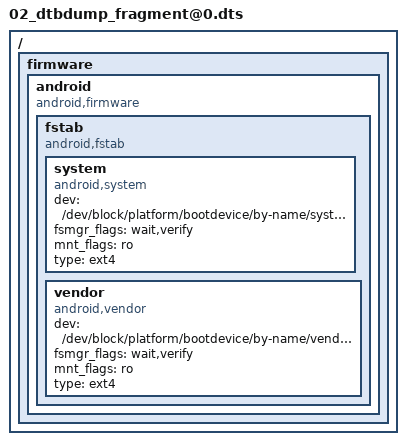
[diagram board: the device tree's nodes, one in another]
/dts-v1/;

/ {

	__fixups__ {
		accdet = "/fragment@15:target:0", "/fragment@66:target:0";
		apuart0 = "/fragment@20:target:0";
		audgpio = "/fragment@16:target:0";
		auxadc = "/fragment@45:target:0";
		charger = "/fragment@32:target:0";
		chosen = "/fragment@1:target:0";
		consys = "/fragment@19:target:0";
		dsi_te = "/fragment@70:target:0";
		fpc_interrupt = "/fragment@39:target:0";
		goodix_fp = "/fragment@68:target:0";
		goodix_optical_fp = "/fragment@42:target:0";
		gpio = "/fragment@60:target:0";
		gpio_usage_mapping = "/fragment@59:target:0";
		gyro = "/fragment@65:target:0";
		i2c0 = "/fragment@8:target:0", "/fragment@47:target:0";
		i2c1 = "/fragment@48:target:0";
		i2c10 = "/fragment@57:target:0";
		i2c11 = "/fragment@58:target:0";
		i2c2 = "/fragment@49:target:0";
		i2c3 = "/fragment@5:target:0", "/fragment@9:target:0", "/fragment@13:target:0", "/fragment@50:target:0";
		i2c4 = "/fragment@51:target:0";
		i2c5 = "/fragment@52:target:0";
		i2c6 = "/fragment@34:target:0", "/fragment@53:target:0", "/fragment@85:target:0";
		i2c7 = "/fragment@54:target:0";
		i2c8 = "/fragment@55:target:0";
		i2c9 = "/fragment@56:target:0";
		irq_nfc = "/fragment@63:target:0";
		irtx_pwm = "/fragment@22:target:0";
		kd_camera_hw1 = "/fragment@37:target:0", "/fragment@82:target:0";
		keypad = "/fragment@28:target:0", "/fragment@84:target:0";
		main_pmic = "/fragment@72:target:0";
		md1_sim1_hot_plug_eint = "/fragment@73:target:0";
		md1_sim2_hot_plug_eint = "/fragment@74:target:0";
		mediatek_phy_tuning = "/fragment@3:target:0";
		motor_drv = "/fragment@12:target:0";
		motor_pl = "/fragment@11:target:0";
		mrdump_ext_rst = "/fragment@61:target:0";
		msdc1 = "/fragment@30:target:0";
		msdc1_ins = "/fragment@64:target:0";
		mt6370_pmu = "/fragment@0:target:0", "/fragment@24:target:0";
		mt6370_typec = "/fragment@25:target:0";
		mt_pmic_vcama1_ldo_reg = "/fragment@37/__overlay__:cam0_vcama-supply:0", "/fragment@75:target:0", "/fragment@82/__overlay__:vcama-supply:0";
		mt_pmic_vcama2_ldo_reg = "/fragment@37/__overlay__:cam1_vcama-supply:0", "/fragment@37/__overlay__:cam2_vcama-supply:0", "/fragment@37/__overlay__:cam3_vcama-supply:0", "/fragment@37/__overlay__:cam4_vcama-supply:0", "/fragment@76:target:0", "/fragment@82/__overlay__:vcama_sub-supply:0", "/fragment@82/__overlay__:vcama_sub2-supply:0", "/fragment@82/__overlay__:vcama_main2-supply:0", "/fragment@82/__overlay__:vcama_main3-supply:0";
		mt_pmic_vcamd_ldo_reg = "/fragment@37/__overlay__:cam2_vcamd-supply:0", "/fragment@79:target:0", "/fragment@82/__overlay__:vcamd_main2-supply:0";
		mt_pmic_vcamio_ldo_reg = "/fragment@37/__overlay__:cam0_vcamio-supply:0", "/fragment@37/__overlay__:cam1_vcamio-supply:0", "/fragment@37/__overlay__:cam2_vcamio-supply:0", "/fragment@37/__overlay__:cam3_vcamio-supply:0", "/fragment@37/__overlay__:cam4_vcamio-supply:0", "/fragment@80:target:0", "/fragment@82/__overlay__:vcamio-supply:0", "/fragment@82/__overlay__:vcamio_sub-supply:0", "/fragment@82/__overlay__:vcamio_main2-supply:0", "/fragment@82/__overlay__:vcamio_sub2-supply:0", "/fragment@82/__overlay__:vcamio_main3-supply:0";
		mt_pmic_vldo28_ldo_reg = "/fragment@81:target:0", "/fragment@82/__overlay__:vcamaf-supply:0", "/fragment@83/__overlay__:vtouch-supply:0";
		mt_pmic_vsim1_ldo_reg = "/fragment@77:target:0";
		mt_pmic_vsim2_ldo_reg = "/fragment@78:target:0";
		mtkfb = "/fragment@7:target:0";
		odm = "/fragment@2:target:0";
		oppo_fp_common = "/fragment@44:target:0";
		pio = "/fragment@2/__overlay__/kpd_volume_up:interrupt-parent:0", "/fragment@2/__overlay__/kpd_volume_down:interrupt-parent:0", "/fragment@2/__overlay__/oppo_devinfo:Hw,sub_hwid_1:0", "/fragment@2/__overlay__/oppo_devinfo:Hw,sub_hwid_2:0", "/fragment@2/__overlay__/oppo_devinfo:Hw,main_hwid_5:0", "/fragment@2/__overlay__/oppo_devinfo:Hw,main_hwid_6:0", "/fragment@2/__overlay__/oppo_charger:qcom,chargerid_switch-gpio:0", "/fragment@2/__overlay__/oppo_charger:qcom,ship-gpio:0", "/fragment@2/__overlay__/oppo_charger:qcom,dischg-gpio:0", "/fragment@2/__overlay__/nfc:gpio-rst-std:0", "/fragment@2/__overlay__/nfc:gpio-irq-std:0", "/fragment@6:target:0", "/fragment@8/__overlay__/goodix19151@5d:interrupt-parent:0", "/fragment@8/__overlay__/goodix19151@5d:enable2v8_gpio:0", "/fragment@8/__overlay__/goodix19151@5d:irq-gpio:0", "/fragment@8/__overlay__/goodix19151@5d:reset-gpio:0", "/fragment@9/__overlay__/aw87339@59:reset-gpio:0", "/fragment@10:target:0", "/fragment@12/__overlay__:boost-gpio:0", "/fragment@12/__overlay__:sleep-gpio:0", "/fragment@12/__overlay__:dir-gpio:0", "/fragment@12/__overlay__:step-gpio:0", "/fragment@13/__overlay__/dhall0-m1120@0f:interrupt-parent:0", "/fragment@13/__overlay__/dhall0-m1120@0f:dhall,irq-gpio:0", "/fragment@13/__overlay__/dhall0-m1120@0f:hall-power-gpio:0", "/fragment@13/__overlay__/dhall1-m1120@0c:interrupt-parent:0", "/fragment@13/__overlay__/dhall1-m1120@0c:dhall,irq-gpio:0", "/fragment@13/__overlay__/dhall1-m1120@0c:hall-power-gpio:0", "/fragment@14:target:0", "/fragment@17:target:0", "/fragment@18:target:0", "/fragment@21:target:0", "/fragment@23:target:0", "/fragment@24/__overlay__:mt6370,intr_gpio:0", "/fragment@25/__overlay__:mt6370pd,intr_gpio:0", "/fragment@27:target:0", "/fragment@28/__overlay__:keypad,volume-up:0", "/fragment@28/__overlay__:keypad,volume-down:0", "/fragment@29:target:0", "/fragment@31:target:0", "/fragment@33:target:0", "/fragment@34/__overlay__/rk826_fastcg@0a:qcom,charging_switch1-gpio:0", "/fragment@34/__overlay__/rk826_fastcg@0a:qcom,charging_switch1_ctr1-gpio:0", "/fragment@34/__overlay__/rk826_fastcg@0a:qcom,charging_reset-gpio:0", "/fragment@34/__overlay__/rk826_fastcg@0a:qcom,charging_clock-gpio:0", "/fragment@34/__overlay__/rk826_fastcg@0a:qcom,charging_data-gpio:0", "/fragment@34/__overlay__/stm8s_fastcg@26:qcom,charging_switch1-gpio:0", "/fragment@34/__overlay__/stm8s_fastcg@26:qcom,charging_reset-gpio:0", "/fragment@34/__overlay__/stm8s_fastcg@26:qcom,charging_clock-gpio:0", "/fragment@34/__overlay__/stm8s_fastcg@26:qcom,charging_data-gpio:0", "/fragment@35:target:0", "/fragment@36:target:0", "/fragment@38:target:0", "/fragment@39/__overlay__:fpc,irq-gpio:0", "/fragment@39/__overlay__:fpc,reset-gpio:0", "/fragment@39/__overlay__:fpc,vdd-en:0", "/fragment@39/__overlay__:fpc,gpio_cs:0", "/fragment@40:target:0", "/fragment@41/__overlay__/fingerprint@0:pw_en_gpio:0", "/fragment@41/__overlay__/fingerprint@0:vddio_en:0", "/fragment@42/__overlay__:goodix,gpio_irq:0", "/fragment@42/__overlay__:goodix,gpio_reset:0", "/fragment@42/__overlay__:goodix,pw_en:0", "/fragment@42/__overlay__:goodix,gpio_cs:0", "/fragment@43:target:0", "/fragment@44/__overlay__:oppo,fp-id0:0", "/fragment@48/__overlay__/alsps@51:interrupt-parent:0", "/fragment@59/__overlay__:GPIO_FDD_BAND_SUPPORT_DETECT_5TH_PIN:0", "/fragment@59/__overlay__:GPIO_SIM2_SIO:0", "/fragment@59/__overlay__:GPIO_SIM2_SRST:0", "/fragment@59/__overlay__:GPIO_SIM2_SCLK:0", "/fragment@59/__overlay__:GPIO_SIM1_SCLK:0", "/fragment@59/__overlay__:GPIO_SIM1_SRST:0", "/fragment@59/__overlay__:GPIO_SIM1_SIO:0", "/fragment@59/__overlay__:GPIO_SIM1_HOT_PLUG:0", "/fragment@59/__overlay__:GPIO_FDD_BAND_SUPPORT_DETECT_6TH_PIN:0", "/fragment@59/__overlay__:GPIO_FDD_BAND_SUPPORT_DETECT_2ND_PIN:0", "/fragment@61/__overlay__:interrupt-parent:0", "/fragment@61/__overlay__:deb-gpios:0", "/fragment@62/__overlay__:interrupt-parent:0", "/fragment@63/__overlay__:interrupt-parent:0", "/fragment@64/__overlay__:interrupt-parent:0", "/fragment@64/__overlay__:deb-gpios:0", "/fragment@65/__overlay__:interrupt-parent:0", "/fragment@66/__overlay__:interrupt-parent:0", "/fragment@66/__overlay__:deb-gpios:0", "/fragment@67/__overlay__:interrupt-parent:0", "/fragment@68/__overlay__:interrupt-parent:0", "/fragment@69/__overlay__:interrupt-parent:0", "/fragment@70/__overlay__:interrupt-parent:0", "/fragment@71/__overlay__:interrupt-parent:0", "/fragment@72/__overlay__:interrupt-parent:0", "/fragment@86:target:0", "/fragment@87:target:0";
		pmic_clock_buffer_ctrl = "/fragment@46:target:0";
		rt9465_slave_chr = "/fragment@67:target:0";
		scp = "/fragment@4:target:0";
		spi0 = "/fragment@41:target:0";
		ssusb_ip_sleep = "/fragment@26:target:0";
		subpmic_pmu_eint = "/fragment@71:target:0";
		tcpc_pd = "/fragment@69:target:0";
		touch = "/fragment@62:target:0", "/fragment@83:target:0";
	};

	__local_fixups__ {

		fragment@12 {

			__overlay__ {
				pinctrl-0 = <0x0>;
				pinctrl-1 = <0x0 0x4 0x8 0xc>;
				pinctrl-2 = <0x0 0x4 0x8 0xc>;
			};
		};

		fragment@13 {

			__overlay__ {

				dhall0-m1120@0f {
					pinctrl-0 = <0x0>;
					pinctrl-1 = <0x0>;
					pinctrl-2 = <0x0>;
				};

				dhall1-m1120@0c {
					pinctrl-0 = <0x0>;
					pinctrl-1 = <0x0>;
					pinctrl-2 = <0x0>;
				};
			};
		};

		fragment@16 {

			__overlay__ {
				pinctrl-0 = <0x0>;
				pinctrl-1 = <0x0>;
				pinctrl-10 = <0x0>;
				pinctrl-11 = <0x0>;
				pinctrl-2 = <0x0>;
				pinctrl-3 = <0x0>;
				pinctrl-4 = <0x0>;
				pinctrl-5 = <0x0>;
				pinctrl-6 = <0x0>;
				pinctrl-7 = <0x0>;
				pinctrl-8 = <0x0>;
				pinctrl-9 = <0x0>;
			};
		};

		fragment@19 {

			__overlay__ {
				pinctrl-0 = <0x0>;
				pinctrl-1 = <0x0>;
				pinctrl-2 = <0x0>;
				pinctrl-3 = <0x0>;
			};
		};

		fragment@2 {

			__overlay__ {

				oppo_charger {
					pinctrl-0 = <0x0>;
					pinctrl-1 = <0x0>;
					pinctrl-2 = <0x0>;
					pinctrl-3 = <0x0>;
					pinctrl-4 = <0x0>;
					pinctrl-5 = <0x0>;
					pinctrl-6 = <0x0>;
				};

				oppo_devinfo {
					pinctrl-0 = <0x0>;
					pinctrl-1 = <0x0 0x4>;
					pinctrl-2 = <0x0 0x4>;
					pinctrl-3 = <0x0>;
					pinctrl-4 = <0x0>;
				};

				usb_c_pinctrl {
					pinctrl-0 = <0x0>;
					pinctrl-1 = <0x0>;
					pinctrl-10 = <0x0>;
					pinctrl-11 = <0x0>;
					pinctrl-12 = <0x0>;
					pinctrl-2 = <0x0>;
					pinctrl-3 = <0x0>;
					pinctrl-4 = <0x0>;
					pinctrl-5 = <0x0>;
					pinctrl-6 = <0x0>;
					pinctrl-7 = <0x0>;
					pinctrl-8 = <0x0>;
					pinctrl-9 = <0x0>;
				};
			};
		};

		fragment@20 {

			__overlay__ {
				pinctrl-0 = <0x0>;
				pinctrl-1 = <0x0>;
				pinctrl-2 = <0x0>;
				pinctrl-3 = <0x0>;
				pinctrl-4 = <0x0>;
				pinctrl-5 = <0x0>;
				pinctrl-6 = <0x0>;
			};
		};

		fragment@22 {

			__overlay__ {
				pinctrl-0 = <0x0>;
				pinctrl-1 = <0x0>;
			};
		};

		fragment@28 {

			__overlay__ {
				pinctrl-0 = <0x0>;
				pinctrl-1 = <0x0>;
			};
		};

		fragment@30 {

			__overlay__ {
				pinctrl-0 = <0x0>;
				pinctrl-1 = <0x0>;
			};
		};

		fragment@34 {

			__overlay__ {

				rk826_fastcg@0a {
					pinctrl-0 = <0x0>;
					pinctrl-1 = <0x0>;
					pinctrl-10 = <0x0>;
					pinctrl-11 = <0x0>;
					pinctrl-12 = <0x0>;
					pinctrl-13 = <0x0>;
					pinctrl-2 = <0x0>;
					pinctrl-3 = <0x0>;
					pinctrl-4 = <0x0>;
					pinctrl-5 = <0x0>;
					pinctrl-6 = <0x0>;
					pinctrl-7 = <0x0>;
					pinctrl-8 = <0x0>;
					pinctrl-9 = <0x0>;
				};

				stm8s_fastcg@26 {
					pinctrl-0 = <0x0>;
					pinctrl-1 = <0x0>;
					pinctrl-10 = <0x0>;
					pinctrl-11 = <0x0>;
					pinctrl-2 = <0x0>;
					pinctrl-3 = <0x0>;
					pinctrl-4 = <0x0>;
					pinctrl-5 = <0x0>;
					pinctrl-6 = <0x0>;
					pinctrl-7 = <0x0>;
					pinctrl-8 = <0x0>;
					pinctrl-9 = <0x0>;
				};
			};
		};

		fragment@37 {

			__overlay__ {
				pinctrl-0 = <0x0>;
				pinctrl-1 = <0x0>;
				pinctrl-10 = <0x0>;
				pinctrl-11 = <0x0>;
				pinctrl-12 = <0x0>;
				pinctrl-13 = <0x0>;
				pinctrl-14 = <0x0>;
				pinctrl-15 = <0x0>;
				pinctrl-16 = <0x0>;
				pinctrl-17 = <0x0>;
				pinctrl-18 = <0x0>;
				pinctrl-19 = <0x0>;
				pinctrl-2 = <0x0>;
				pinctrl-20 = <0x0>;
				pinctrl-21 = <0x0>;
				pinctrl-22 = <0x0>;
				pinctrl-23 = <0x0>;
				pinctrl-24 = <0x0>;
				pinctrl-25 = <0x0>;
				pinctrl-26 = <0x0>;
				pinctrl-27 = <0x0>;
				pinctrl-28 = <0x0>;
				pinctrl-29 = <0x0>;
				pinctrl-3 = <0x0>;
				pinctrl-30 = <0x0>;
				pinctrl-31 = <0x0>;
				pinctrl-32 = <0x0>;
				pinctrl-33 = <0x0>;
				pinctrl-34 = <0x0>;
				pinctrl-35 = <0x0>;
				pinctrl-36 = <0x0>;
				pinctrl-37 = <0x0>;
				pinctrl-38 = <0x0>;
				pinctrl-39 = <0x0>;
				pinctrl-4 = <0x0>;
				pinctrl-40 = <0x0>;
				pinctrl-41 = <0x0>;
				pinctrl-5 = <0x0>;
				pinctrl-6 = <0x0>;
				pinctrl-7 = <0x0>;
				pinctrl-8 = <0x0>;
				pinctrl-9 = <0x0>;
			};
		};

		fragment@39 {

			__overlay__ {
				pinctrl-0 = <0x0 0x4 0x8>;
				pinctrl-1 = <0x0>;
			};
		};

		fragment@42 {

			__overlay__ {
				pinctrl-0 = <0x0 0x4>;
				pinctrl-1 = <0x0 0x4 0x8 0xc>;
				pinctrl-2 = <0x0>;
				pinctrl-3 = <0x0 0x4 0x8 0xc>;
			};
		};

		fragment@7 {

			__overlay__ {
				pinctrl-0 = <0x0>;
				pinctrl-1 = <0x0>;
				pinctrl-2 = <0x0>;
				pinctrl-3 = <0x0>;
				pinctrl-4 = <0x0>;
				pinctrl-5 = <0x0>;
				pinctrl-6 = <0x0>;
				pinctrl-7 = <0x0>;
				pinctrl-8 = <0x0>;
			};
		};

		fragment@85 {

			__overlay__ {
				pinctrl-0 = <0x0>;
				pinctrl-1 = <0x0>;
			};
		};
	};

	__symbols__ {
		alsps_mtk = "/fragment@48/__overlay__/alsps@51";
		aud_clk_mosi_off = "/fragment@17/__overlay__/aud_clk_mosi_off";
		aud_clk_mosi_on = "/fragment@17/__overlay__/aud_clk_mosi_on";
		aud_dat_miso_off = "/fragment@17/__overlay__/aud_dat_miso_off";
		aud_dat_miso_on = "/fragment@17/__overlay__/aud_dat_miso_on";
		aud_dat_mosi_off = "/fragment@17/__overlay__/aud_dat_mosi_off";
		aud_dat_mosi_on = "/fragment@17/__overlay__/aud_dat_mosi_on";
		aud_pins_hpamp_high = "/fragment@17/__overlay__/audhpamphigh";
		aud_pins_hpamp_low = "/fragment@17/__overlay__/audhpamplow";
		aud_pins_i2s0_mode0 = "/fragment@17/__overlay__/audi2s0mode0";
		aud_pins_i2s0_mode1 = "/fragment@17/__overlay__/audi2s0mode1";
		aud_pins_i2s1_mode0 = "/fragment@17/__overlay__/audi2s1mode0";
		aud_pins_i2s1_mode1 = "/fragment@17/__overlay__/audi2s1mode1";
		barometer_mtk = "/fragment@48/__overlay__/barometer@77";
		bat_gm30 = "/fragment@2/__overlay__/bat_gm30";
		boost_active = "/fragment@10/__overlay__/boost_active";
		boost_sleep = "/fragment@10/__overlay__/boost_sleep";
		camera_main_af_mtk = "/fragment@51/__overlay__/camera_main_af@72";
		camera_main_eeprom_mtk = "/fragment@51/__overlay__/camera_main_eeprom@50";
		camera_main_mtk = "/fragment@51/__overlay__/camera_main@1a";
		camera_main_three_mtk = "/fragment@49/__overlay__/camera_main_three@66";
		camera_main_two_af_mtk = "/fragment@49/__overlay__/camera_main_two_af@72";
		camera_main_two_eeprom_mtk = "/fragment@49/__overlay__/camera_main_two_eeprom@51";
		camera_main_two_mtk = "/fragment@49/__overlay__/camera_main_two@10";
		camera_mipi_switch_high = "/fragment@36/__overlay__/camera_mipi_switch_output_high@gpio76";
		camera_mipi_switch_low = "/fragment@36/__overlay__/camera_mipi_switch_output_low@gpio76";
		camera_pins_cam0_mclk_2ma = "/fragment@36/__overlay__/camera_pins_cam0_mclk_2ma";
		camera_pins_cam0_mclk_4ma = "/fragment@36/__overlay__/camera_pins_cam0_mclk_4ma";
		camera_pins_cam0_mclk_6ma = "/fragment@36/__overlay__/camera_pins_cam0_mclk_6ma";
		camera_pins_cam0_mclk_8ma = "/fragment@36/__overlay__/camera_pins_cam0_mclk_8ma";
		camera_pins_cam0_mclk_off = "/fragment@36/__overlay__/camera_pins_cam0_mclk_off";
		camera_pins_cam0_rst_0 = "/fragment@36/__overlay__/cam0@0";
		camera_pins_cam0_rst_1 = "/fragment@36/__overlay__/cam0@1";
		camera_pins_cam0_vcamd_0 = "/fragment@36/__overlay__/cam0@vcam0";
		camera_pins_cam0_vcamd_1 = "/fragment@36/__overlay__/cam0@vcam1";
		camera_pins_cam1_mclk_2ma = "/fragment@36/__overlay__/camera_pins_cam1_mclk_2ma";
		camera_pins_cam1_mclk_4ma = "/fragment@36/__overlay__/camera_pins_cam1_mclk_4ma";
		camera_pins_cam1_mclk_6ma = "/fragment@36/__overlay__/camera_pins_cam1_mclk_6ma";
		camera_pins_cam1_mclk_8ma = "/fragment@36/__overlay__/camera_pins_cam1_mclk_8ma";
		camera_pins_cam1_mclk_off = "/fragment@36/__overlay__/camera_pins_cam1_mclk_off";
		camera_pins_cam1_rst_0 = "/fragment@36/__overlay__/cam1@0";
		camera_pins_cam1_rst_1 = "/fragment@36/__overlay__/cam1@1";
		camera_pins_cam1_vcamd_0 = "/fragment@36/__overlay__/cam1@vcamd0";
		camera_pins_cam1_vcamd_1 = "/fragment@36/__overlay__/cam1@vcamd1";
		camera_pins_cam2_mclk_2ma = "/fragment@36/__overlay__/camera_pins_cam2_mclk_2ma";
		camera_pins_cam2_mclk_4ma = "/fragment@36/__overlay__/camera_pins_cam2_mclk_4ma";
		camera_pins_cam2_mclk_6ma = "/fragment@36/__overlay__/camera_pins_cam2_mclk_6ma";
		camera_pins_cam2_mclk_8ma = "/fragment@36/__overlay__/camera_pins_cam2_mclk_8ma";
		camera_pins_cam2_mclk_off = "/fragment@36/__overlay__/camera_pins_cam2_mclk_off";
		camera_pins_cam2_rst_0 = "/fragment@36/__overlay__/cam2@0";
		camera_pins_cam2_rst_1 = "/fragment@36/__overlay__/cam2@1";
		camera_pins_cam3_mclk_2ma = "/fragment@36/__overlay__/camera_pins_cam3_mclk_2ma";
		camera_pins_cam3_mclk_4ma = "/fragment@36/__overlay__/camera_pins_cam3_mclk_4ma";
		camera_pins_cam3_mclk_6ma = "/fragment@36/__overlay__/camera_pins_cam3_mclk_6ma";
		camera_pins_cam3_mclk_8ma = "/fragment@36/__overlay__/camera_pins_cam3_mclk_8ma";
		camera_pins_cam3_mclk_off = "/fragment@36/__overlay__/camera_pins_cam3_mclk_off";
		camera_pins_cam3_rst_0 = "/fragment@36/__overlay__/cam3@0";
		camera_pins_cam3_rst_1 = "/fragment@36/__overlay__/cam3@1";
		camera_pins_cam4_mclk_2ma = "/fragment@36/__overlay__/camera_pins_cam4_mclk_2ma";
		camera_pins_cam4_mclk_4ma = "/fragment@36/__overlay__/camera_pins_cam4_mclk_4ma";
		camera_pins_cam4_mclk_6ma = "/fragment@36/__overlay__/camera_pins_cam4_mclk_6ma";
		camera_pins_cam4_mclk_8ma = "/fragment@36/__overlay__/camera_pins_cam4_mclk_8ma";
		camera_pins_cam4_mclk_off = "/fragment@36/__overlay__/camera_pins_cam4_mclk_off";
		camera_pins_cam4_rst_0 = "/fragment@36/__overlay__/cam4@0";
		camera_pins_cam4_rst_1 = "/fragment@36/__overlay__/cam4@1";
		camera_pins_default = "/fragment@36/__overlay__/camdefault";
		camera_sub_eeprom_mtk = "/fragment@51/__overlay__/camera_sub_eeprom@54";
		camera_sub_mtk = "/fragment@51/__overlay__/camera_sub@35";
		camera_sub_two_mtk = "/fragment@51/__overlay__/camera_sub_two@56";
		cap_touch_mtk = "/fragment@47/__overlay__/cap_touch@5d";
		ccu_sensor_i2c_2_hw_mtk = "/fragment@49/__overlay__/ccu_sensor_i2c_2_hw@36";
		ccu_sensor_i2c_4_hw_mtk = "/fragment@51/__overlay__/ccu_sensor_i2c_4_hw@33";
		charger_pins_default = "/fragment@33/__overlay__/eint0default";
		charger_pins_eint_output0 = "/fragment@33/__overlay__/charger_gpio_as_output_low";
		charger_pins_eint_output1 = "/fragment@33/__overlay__/charger_gpio_as_output_high";
		charging_clock_active = "/fragment@35/__overlay__/charging_clock_active";
		charging_clock_sleep = "/fragment@35/__overlay__/charging_clock_sleep";
		charging_data_active = "/fragment@35/__overlay__/charging_data_active";
		charging_data_sleep = "/fragment@35/__overlay__/charging_data_sleep";
		charging_reset_active = "/fragment@35/__overlay__/charging_reset_active";
		charging_reset_sleep = "/fragment@35/__overlay__/charging_reset_sleep";
		charging_switch1_active = "/fragment@35/__overlay__/charging_switch1_active";
		charging_switch1_ctr1_active = "/fragment@35/__overlay__/charging_switch1_ctr1_active";
		charging_switch1_ctr1_sleep = "/fragment@35/__overlay__/charging_switch1_ctr1_sleep";
		charging_switch1_sleep = "/fragment@35/__overlay__/charging_switch1_sleep";
		consys_pins_default = "/fragment@18/__overlay__/consys_default";
		dir_active = "/fragment@10/__overlay__/dir_active";
		dir_sleep = "/fragment@10/__overlay__/dir_sleep";
		dischg_disable = "/fragment@33/__overlay__/dischg_disable";
		dischg_enable = "/fragment@33/__overlay__/dischg_enable";
		fpc_irq_default = "/fragment@38/__overlay__/fpc_irq_default";
		fpc_pwr_default = "/fragment@38/__overlay__/fpc_pwr_default";
		fpc_reset_default = "/fragment@38/__overlay__/fpc_reset_default";
		fuelgauge = "/fragment@2/__overlay__/fuelgauge";
		gpio_fpc_cs_func = "/fragment@38/__overlay__/gpio_fpc_cs_func";
		gpio_goodix_clk_6mA = "/fragment@40/__overlay__/gpio_goodix_clk_6mA";
		gpio_goodix_clk_6mA_pulllow = "/fragment@40/__overlay__/gpio_goodix_clk_6mA_pulllow";
		gpio_goodix_cs_6mA = "/fragment@40/__overlay__/gpio_goodix_cs_6mA";
		gpio_goodix_cs_6mA_pulllow = "/fragment@40/__overlay__/gpio_goodix_cs_6mA_pulllow";
		gpio_goodix_cs_func = "/fragment@40/__overlay__/gpio_goodix_cs_func";
		gpio_goodix_irq_default = "/fragment@40/__overlay__/gpio_goodix_irq_default";
		gpio_goodix_miso_6mA = "/fragment@40/__overlay__/gpio_goodix_miso_6mA";
		gpio_goodix_miso_6mA_pulllow = "/fragment@40/__overlay__/gpio_goodix_miso_6mA_pulllow";
		gpio_goodix_mosi_6mA = "/fragment@40/__overlay__/gpio_goodix_mosi_6mA";
		gpio_goodix_mosi_6mA_pulllow = "/fragment@40/__overlay__/gpio_goodix_mosi_6mA_pulllow";
		gpio_goodix_reset_default = "/fragment@40/__overlay__/gpio_goodix_reset_default";
		gpio_id0_default = "/fragment@43/__overlay__/gpio_id0_default";
		gpio_redriver_c1_high = "/fragment@27/__overlay__/c1_high";
		gpio_redriver_c1_hiz = "/fragment@27/__overlay__/c1_highz";
		gpio_redriver_c1_init = "/fragment@27/__overlay__/c1_init";
		gpio_redriver_c1_low = "/fragment@27/__overlay__/c1_low";
		gpio_redriver_c2_high = "/fragment@27/__overlay__/c2_high";
		gpio_redriver_c2_hiz = "/fragment@27/__overlay__/c2_highz";
		gpio_redriver_c2_init = "/fragment@27/__overlay__/c2_init";
		gpio_redriver_c2_low = "/fragment@27/__overlay__/c2_low";
		gpio_u3_switch_disable = "/fragment@27/__overlay__/u3_sw_dis";
		gpio_u3_switch_enable = "/fragment@27/__overlay__/u3_sw_en";
		gpio_u3_switch_sel1 = "/fragment@27/__overlay__/u3_sw_sel1";
		gpio_u3_switch_sel2 = "/fragment@27/__overlay__/u3_sw_sel2";
		gpslna_pins_init = "/fragment@18/__overlay__/gpslna@0";
		gpslna_pins_oh = "/fragment@18/__overlay__/gpslna@1";
		gpslna_pins_ol = "/fragment@18/__overlay__/gpslna@2";
		hall0_interrupt_input = "/fragment@14/__overlay__/hall0_interrupt_input";
		hall1_interrupt_input = "/fragment@14/__overlay__/hall1_interrupt_input";
		hall_power_down = "/fragment@14/__overlay__/hall_power_down";
		hall_power_up = "/fragment@14/__overlay__/hall_power_up";
		hw_main_id5_active = "/fragment@87/__overlay__/active@id5";
		hw_main_id6_active = "/fragment@87/__overlay__/active@id6";
		hw_pins_default = "/fragment@87/__overlay__/default@hw_sub_id";
		hw_pins_sub_id1_active = "/fragment@87/__overlay__/active@id1";
		hw_pins_sub_id1_sleep = "/fragment@87/__overlay__/sleep@id1";
		hw_pins_sub_id2_active = "/fragment@87/__overlay__/active@id2";
		hw_pins_sub_id2_sleep = "/fragment@87/__overlay__/sleep@id2";
		i2c6_i2c_state = "/fragment@86/__overlay__/i2c6_sda_i2c_state";
		i2c6_output_low_state = "/fragment@86/__overlay__/i2c6_sda_output_low_state";
		irtx_gpio_led_default = "/fragment@23/__overlay__/irtx_gpio_led_def@gpio90";
		irtx_gpio_led_set = "/fragment@23/__overlay__/irtx_gpio_led_set@gpio90";
		kpd_volume_down = "/fragment@2/__overlay__/kpd_volume_down";
		kpd_volume_up = "/fragment@2/__overlay__/kpd_volume_up";
		led0 = "/fragment@2/__overlay__/led@0";
		led1 = "/fragment@2/__overlay__/led@1";
		led2 = "/fragment@2/__overlay__/led@2";
		led3 = "/fragment@2/__overlay__/led@3";
		led4 = "/fragment@2/__overlay__/led@4";
		led5 = "/fragment@2/__overlay__/led@5";
		led6 = "/fragment@2/__overlay__/led@6";
		motor_default = "/fragment@10/__overlay__/motor_default";
		msdc1_off = "/fragment@31/__overlay__/sd0@1";
		msdc1_on = "/fragment@31/__overlay__/sd0@0";
		msensor_mtk = "/fragment@48/__overlay__/msensor@0c";
		mtkfb_pins_default = "/fragment@6/__overlay__/default";
		mtkfb_pins_lcd_mipi_err_en0 = "/fragment@6/__overlay__/lcd_mipi_err_en0_gpio";
		mtkfb_pins_lcd_mipi_err_en1 = "/fragment@6/__overlay__/lcd_mipi_err_en1_gpio";
		mtkfb_pins_lcd_vci_en0 = "/fragment@6/__overlay__/lcd_vci_en0_gpio";
		mtkfb_pins_lcd_vci_en1 = "/fragment@6/__overlay__/lcd_vci_en1_gpio";
		mtkfb_pins_lcm_reset0 = "/fragment@6/__overlay__/lcm_rst_out0_gpio";
		mtkfb_pins_lcm_reset1 = "/fragment@6/__overlay__/lcm_rst_out1_gpio";
		mtkfb_pins_mode_te_gpio = "/fragment@6/__overlay__/mode_te_gpio";
		mtkfb_pins_mode_te_te = "/fragment@6/__overlay__/mode_te_te";
		nfc = "/fragment@2/__overlay__/nfc";
		nfc_mtk = "/fragment@50/__overlay__/nfc@08";
		oppo_charger = "/fragment@2/__overlay__/oppo_charger";
		oppo_devinfo = "/fragment@2/__overlay__/oppo_devinfo";
		oppo_fp = "/fragment@41/__overlay__/fingerprint@0";
		oppo_project = "/fragment@2/__overlay__/oppo_project";
		oppo_sensor = "/fragment@2/__overlay__/oppo_sensor";
		pwm_active = "/fragment@10/__overlay__/pwm_active";
		pwm_sleep = "/fragment@10/__overlay__/pwm_sleep";
		ship_active_gpio = "/fragment@33/__overlay__/ship_active";
		ship_sleep_gpio = "/fragment@33/__overlay__/ship_sleep";
		shortc_active_gpio = "/fragment@33/__overlay__/shortc_active";
		slave_charger_mtk = "/fragment@53/__overlay__/slave_charger@4b";
		sleep_active = "/fragment@10/__overlay__/sleep_active";
		sleep_sleep = "/fragment@10/__overlay__/sleep_sleep";
		strobe_main_2_mtk = "/fragment@51/__overlay__/strobe_main_2@64";
		strobe_main_mtk = "/fragment@51/__overlay__/strobe_main@63";
		subpmic_pmu_mtk = "/fragment@52/__overlay__/subpmic_pmu@34";
		uart0_gpio_def_cfg = "/fragment@21/__overlay__/uart0gpiodefault";
		uart0_rx_clr_cfg = "/fragment@21/__overlay__/uart0_rx_clear@gpio95";
		uart0_rx_gpio_input = "/fragment@21/__overlay__/uart0_rx_gpio@gpio95";
		uart0_rx_set_cfg = "/fragment@21/__overlay__/uart0_rx_set@gpio95";
		uart0_tx_clr_cfg = "/fragment@21/__overlay__/uart0_tx_clear@gpio96";
		uart0_tx_gpio_input = "/fragment@21/__overlay__/uart0_tx_gpio@gpio96";
		uart0_tx_set_cfg = "/fragment@21/__overlay__/uart0_tx_set@gpio96";
		usb_c_pinctrl = "/fragment@2/__overlay__/usb_c_pinctrl";
		usb_default = "/fragment@27/__overlay__/usb_default";
		usb_type_c_mtk = "/fragment@52/__overlay__/usb_type_c@4e";
		vibrator0 = "/fragment@2/__overlay__/vibrator@0";
		volume_down_gpio_eint = "/fragment@29/__overlay__/volume_down@0";
		volume_up_gpio_eint = "/fragment@29/__overlay__/volume_up@0";
		vooc_ap_data = "/fragment@2/__overlay__/vooc_ap_data";
		vooc_ap_data_new_function = "/fragment@2/__overlay__/vooc_ap_data_new_function";
	};

	firmware {

		android {
			compatible = "android,firmware";

			fstab {
				compatible = "android,fstab";

				system {
					compatible = "android,system";
					dev = "/dev/block/platform/bootdevice/by-name/system";
					fsmgr_flags = "wait,verify";
					mnt_flags = "ro";
					type = "ext4";
				};

				vendor {
					compatible = "android,vendor";
					dev = "/dev/block/platform/bootdevice/by-name/vendor";
					fsmgr_flags = "wait,verify";
					mnt_flags = "ro";
					type = "ext4";
				};
			};
		};
	};

	fragment@0 {
		target = <0xffffffff>;

		__overlay__ {

			ldo {
				compatible = "mediatek,mt6370_pmu_ldo";
				interrupt-names = "ldo_oc";
				ldo_oms = <0x1>;
				ldo_vrc_lt = <0x1>;

				mt6370_ldo {
					regulator-always-on = "yes";
					regulator-max-microvolt = <0x2dc6c0>;
					regulator-min-microvolt = <0x2dc6c0>;
					regulator-name = "avdd";
				};
			};
		};
	};

	fragment@1 {
		target = <0xffffffff>;

		__overlay__ {
			atag,videolfb-fb_base_h = <0x0>;
			atag,videolfb-fb_base_l = "^`P";
			atag,videolfb-fps = <0x1770>;
			atag,videolfb-islcm_inited = <0x0>;
			atag,videolfb-islcmfound = <0x1>;
			atag,videolfb-lcmname = "nt35595_fhd_dsi_cmd_truly_nt50358_drv";
			atag,videolfb-vramSize = <0x17bb000>;
		};
	};

	fragment@10 {
		target = <0xffffffff>;

		__overlay__ {

			boost_active {
				phandle = <0x2d>;

				pins_cmd_dat {
					bias-disable;
					drive-strength = <0x3>;
					output-high;
					pinmux = <0xf00>;
					slew-rate = <0x1>;
				};
			};

			boost_sleep {
				phandle = <0x29>;

				pins_cmd_dat {
					bias-pull-down;
					drive-strength = <0x3>;
					output-low;
					pinmux = <0xf00>;
					slew-rate = <0x1>;
				};
			};

			dir_active {
				phandle = <0x2c>;

				pins_cmd_dat {
					bias-disable;
					drive-strength = <0x0>;
					output-low;
					pinmux = <0x1000>;
					slew-rate = <0x1>;
				};
			};

			dir_sleep {
				phandle = <0x28>;

				pins_cmd_dat {
					bias-pull-up;
					drive-strength = <0x0>;
					output-high;
					pinmux = <0x1000>;
					slew-rate = <0x1>;
				};
			};

			motor_default {
				phandle = <0x25>;
			};

			pwm_active {
				phandle = <0x2b>;

				pins_cmd_dat {
					bias-disable;
					drive-strength = <0x0>;
					output-low;
					pinmux = <0x5a01>;
					slew-rate = <0x1>;
				};
			};

			pwm_sleep {
				phandle = <0x27>;

				pins_cmd_dat {
					bias-pull-up;
					drive-strength = <0x0>;
					output-high;
					pinmux = <0x5a00>;
					slew-rate = <0x1>;
				};
			};

			sleep_active {
				phandle = <0x2a>;

				pins_cmd_dat {
					bias-disable;
					drive-strength = <0x0>;
					output-low;
					pinmux = <0xe00>;
					slew-rate = <0x1>;
				};
			};

			sleep_sleep {
				phandle = <0x26>;

				pins_cmd_dat {
					bias-pull-up;
					drive-strength = <0x0>;
					output-high;
					pinmux = <0xe00>;
					slew-rate = <0x1>;
				};
			};
		};
	};

	fragment@11 {
		target = <0xffffffff>;

		__overlay__ {
			compatible = "oppo-motor";
			delay-cycle = <0xe 0xe 0xe>;
			down-speed-param = <0x2 0x2625a>;
			full-speed-param = <0x3f 0x3c8c>;
			hall-data-sign = <0x0>;
			hall-irq-pos = <0xaa>;
			mag_noise_pattern = <0x50 0x190 0x0 0x296 0xc8 0x64 0x64>;
			mag_noise_support;
			motor-retard-pos = <0x1ae>;
			nodetect-speed-param = <0xf 0x3c8c>;
			slow-delay-cycle = <0x1c 0x1c 0x1c>;
			slow-down-speed-param = <0x2 0x2625a>;
			slow-full-speed-param = <0x3f 0x7a12>;
			slow-nodetect-speed-param = <0xf 0x196e6>;
			slow-up-speed-param = <0x5 0x196e6>;
			status = "okay";
			stop-neg-point = <0x3 0x3>;
			stop-pos-point = <0x3 0x3>;
			up-speed-param = <0x5 0x3c8c>;
		};
	};

	fragment@12 {
		target = <0xffffffff>;

		__overlay__ {
			boost-gpio = <0xffffffff 0xf 0x0>;
			compatible = "motor_drv-8834";
			dir-gpio = <0xffffffff 0x10 0x0>;
			pinctrl-0 = <0x25>;
			pinctrl-1 = <0x26 0x27 0x28 0x29>;
			pinctrl-2 = <0x2a 0x2b 0x2c 0x2d>;
			pinctrl-names = "default", "motor_sleep", "motor_active";
			ratio-a = <0x18>;
			ratio-b = <0x730>;
			ratio-c = <0x14>;
			ratio-d = <0x20>;
			sleep-gpio = <0xffffffff 0xe 0x0>;
			status = "okay";
			step-gpio = <0xffffffff 0x5a 0x0>;
		};
	};

	fragment@13 {
		target = <0xffffffff>;

		__overlay__ {
			status = "okay";

			dhall0-m1120@0f {
				compatible = "oppo,dhall-m1120";
				dhall,id = <0x0>;
				dhall,irq-gpio = <0xffffffff 0x5 0x2008>;
				hall-power-gpio = <0xffffffff 0x6e 0x0>;
				interrupt-parent = <0xffffffff>;
				interrupts = <0x5 0x8 0x5 0x0>;
				pinctrl-0 = <0x2e>;
				pinctrl-1 = <0x2f>;
				pinctrl-2 = <0x30>;
				pinctrl-names = "hall_power_down", "hall_power_up", "hall0_interrupt_input";
				reg = <0xf>;
				status = "okay";
			};

			dhall1-m1120@0c {
				compatible = "oppo,dhall-m1120";
				dhall,id = <0x1>;
				dhall,irq-gpio = <0xffffffff 0x6 0x2008>;
				hall-power-gpio = <0xffffffff 0x6e 0x0>;
				interrupt-parent = <0xffffffff>;
				interrupts = <0x6 0x8 0x6 0x0>;
				pinctrl-0 = <0x2e>;
				pinctrl-1 = <0x2f>;
				pinctrl-2 = <0x31>;
				pinctrl-names = "hall_power_down", "hall_power_up", "hall1_interrupt_input";
				reg = <0xc>;
				status = "okay";
			};
		};
	};

	fragment@14 {
		target = <0xffffffff>;

		__overlay__ {

			hall0_interrupt_input {
				phandle = <0x30>;

				pins_cmd_dat {
					bias-disable;
					drive-strength = <0x2>;
					pinmux = <0x600>;
					slew-rate = <0x0>;
				};
			};

			hall1_interrupt_input {
				phandle = <0x31>;

				pins_cmd_dat {
					bias-disable;
					drive-strength = <0x2>;
					pinmux = <0x500>;
					slew-rate = <0x0>;
				};
			};

			hall_power_down {
				phandle = <0x2e>;

				pins_cmd_dat {
					bias-pull-down;
					drive-strength = <0x2>;
					output-low;
					pinmux = <0x6e00>;
					slew-rate = <0x1>;
				};
			};

			hall_power_up {
				phandle = <0x2f>;

				pins_cmd_dat {
					bias-pull-down;
					drive-strength = <0x2>;
					output-high;
					pinmux = <0x6e00>;
					slew-rate = <0x1>;
				};
			};
		};
	};

	fragment@15 {
		target = <0xffffffff>;

		__overlay__ {
			accdet-mic-mode = <0x1>;
			accdet-mic-vol = <0x7>;
			accdet-plugout-debounce = <0x1>;
			headset-eint-level-pol = <0x8>;
			headset-four-key-threshold = <0x0 0x3a 0x79 0xc0 0x190>;
			headset-mode-setting = <0x500 0x500 0x1 0x1f0 0x800 0x800 0x20 0x44>;
			headset-three-key-threshold = <0x0 0x52 0xaa 0x132>;
			headset-three-key-threshold-CDD = <0x0 0x79 0xc0 0x258>;
			status = "okay";
		};
	};

	fragment@16 {
		target = <0xffffffff>;

		__overlay__ {
			pinctrl-0 = <0x32>;
			pinctrl-1 = <0x33>;
			pinctrl-10 = <0x3c>;
			pinctrl-11 = <0x3d>;
			pinctrl-2 = <0x34>;
			pinctrl-3 = <0x35>;
			pinctrl-4 = <0x36>;
			pinctrl-5 = <0x37>;
			pinctrl-6 = <0x38>;
			pinctrl-7 = <0x39>;
			pinctrl-8 = <0x3a>;
			pinctrl-9 = <0x3b>;
			pinctrl-names = "aud_dat_mosi_off", "aud_dat_mosi_on", "aud_dat_miso_off", "aud_dat_miso_on", "hpamp-pullhigh", "hpamp-pulllow", "aud_clk_mosi_off", "aud_clk_mosi_on", "audi2s0-mode0", "audi2s0-mode1", "audi2s1-mode0", "audi2s1-mode1";
			status = "okay";
		};
	};

	fragment@17 {
		target = <0xffffffff>;

		__overlay__ {

			aud_clk_mosi_off {
				phandle = <0x38>;
			};

			aud_clk_mosi_on {
				phandle = <0x39>;
			};

			aud_dat_miso_off {
				phandle = <0x34>;
			};

			aud_dat_miso_on {
				phandle = <0x35>;
			};

			aud_dat_mosi_off {
				phandle = <0x32>;
			};

			aud_dat_mosi_on {
				phandle = <0x33>;
			};

			audhpamphigh {
				phandle = <0x36>;
			};

			audhpamplow {
				phandle = <0x37>;
			};

			audi2s0mode0 {
				phandle = <0x3a>;

				pins_cmd_dat {
					pinmux = <0xae00>;
				};
			};

			audi2s0mode1 {
				phandle = <0x3b>;

				pins_cmd_dat {
					pinmux = <0xae02>;
				};
			};

			audi2s1mode0 {
				phandle = <0x3c>;

				pins_cmd0_dat {
					pinmux = <0xaa00>;
				};

				pins_cmd1_dat {
					pinmux = <0xab00>;
				};

				pins_cmd2_dat {
					pinmux = <0xac00>;
				};
			};

			audi2s1mode1 {
				phandle = <0x3d>;

				pins_cmd0_dat {
					pinmux = <0xaa02>;
				};

				pins_cmd1_dat {
					pinmux = <0xab02>;
				};

				pins_cmd2_dat {
					pinmux = <0xac02>;
				};
			};
		};
	};

	fragment@18 {
		target = <0xffffffff>;

		__overlay__ {

			consys_default {
				phandle = <0x3e>;
			};

			gpslna@0 {
				phandle = <0x3f>;

				pins_cmd_dat {
					bias-disable;
					output-low;
					pinmux = <0xa900>;
					slew-rate = <0x1>;
				};
			};

			gpslna@1 {
				phandle = <0x40>;

				pins_cmd_dat {
					output-high;
					pinmux = <0xa900>;
					slew-rate = <0x1>;
				};
			};

			gpslna@2 {
				phandle = <0x41>;

				pins_cmd_dat {
					output-low;
					pinmux = <0xa900>;
					slew-rate = <0x1>;
				};
			};
		};
	};

	fragment@19 {
		target = <0xffffffff>;

		__overlay__ {
			pinctrl-0 = <0x3e>;
			pinctrl-1 = <0x3f>;
			pinctrl-2 = <0x40>;
			pinctrl-3 = <0x41>;
			pinctrl-names = "default", "gps_lna_state_init", "gps_lna_state_oh", "gps_lna_state_ol";
			status = "okay";
		};
	};

	fragment@2 {
		target = <0xffffffff>;

		__overlay__ {

			bat_gm30 {
				CAR_TUNE_VALUE = <0x64>;
				DIFFERENCE_FULLOCV_ITH = <0xc8>;
				EMBEDDED_SEL = <0x1>;
				FG_METER_RESISTANCE = <0x32>;
				KEEP_100_PERCENT = <0x3>;
				PMIC_MIN_VOL = <0x84d0>;
				PMIC_SHUTDOWN_CURRENT = <0x14>;
				POWERON_SYSTEM_IBOOT = <0x1f4>;
				Q_MAX_SYS_VOLTAGE_BAT0 = <0xd16>;
				Q_MAX_SYS_VOLTAGE_BAT1 = <0xd16>;
				Q_MAX_SYS_VOLTAGE_BAT2 = <0xd16>;
				Q_MAX_SYS_VOLTAGE_BAT3 = <0xd16>;
				R_FG_VALUE = <0xa>;
				SHUTDOWN_1_TIME = <0x3c>;
				SHUTDOWN_GAUGE0_VOLTAGE = <0x84d0>;
				TEMPERATURE_T0 = <0x32>;
				TEMPERATURE_T1 = <0x19>;
				TEMPERATURE_T2 = <0xa>;
				TEMPERATURE_T3 = <0x0>;
				TEMPERATURE_T4 = <0xfffffff6>;
				compatible = "mediatek,bat_gm30";
				g_FG_PSEUDO100_T0 = <0x64>;
				g_FG_PSEUDO100_T1 = <0x64>;
				g_FG_PSEUDO100_T2 = <0x64>;
				g_FG_PSEUDO100_T3 = <0x64>;
				g_FG_PSEUDO100_T4 = <0x64>;
				g_FG_PSEUDO1_T0 = <0x0>;
				g_FG_PSEUDO1_T1 = <0x0>;
				g_FG_PSEUDO1_T2 = <0x0>;
				g_FG_PSEUDO1_T3 = <0x0>;
				g_FG_PSEUDO1_T4 = <0x0>;
				phandle = <0x94>;
			};

			fuelgauge {
				compatible = "mediatek, fuelgauge";
				enabled = <0x0>;
				phandle = <0xa7>;
			};

			kpd_volume_down {
				compatible = "mediatek, VOLUME_DOWN-eint";
				debounce = <0x7d00>;
				interrupt-parent = <0xffffffff>;
				interrupts = <0x5e 0x2 0x5e 0x0>;
				phandle = <0xa0>;
				status = "okay";
			};

			kpd_volume_up {
				compatible = "mediatek, VOLUME_UP-eint";
				debounce = <0x7d00>;
				interrupt-parent = <0xffffffff>;
				interrupts = <0x14 0x2 0x14 0x0>;
				phandle = <0x9f>;
				status = "okay";
			};

			led@0 {
				compatible = "mediatek,red";
				data = <0x1>;
				led_mode = <0x0>;
				phandle = <0x95>;
				pwm_config = <0x0 0x0 0x0 0x0 0x0>;
			};

			led@1 {
				compatible = "mediatek,green";
				data = <0x1>;
				led_mode = <0x0>;
				phandle = <0x96>;
				pwm_config = <0x0 0x0 0x0 0x0 0x0>;
			};

			led@2 {
				compatible = "mediatek,blue";
				data = <0x1>;
				led_mode = <0x0>;
				phandle = <0x97>;
				pwm_config = <0x0 0x0 0x0 0x0 0x0>;
			};

			led@3 {
				compatible = "mediatek,jogball-backlight";
				data = <0x1>;
				led_mode = <0x0>;
				phandle = <0x98>;
				pwm_config = <0x0 0x0 0x0 0x0 0x0>;
			};

			led@4 {
				compatible = "mediatek,keyboard-backlight";
				data = <0x1>;
				led_mode = <0x0>;
				phandle = <0x99>;
				pwm_config = <0x0 0x0 0x0 0x0 0x0>;
			};

			led@5 {
				compatible = "mediatek,button-backlight";
				data = <0x1>;
				led_mode = <0x0>;
				phandle = <0x9a>;
				pwm_config = <0x0 0x0 0x0 0x0 0x0>;
			};

			led@6 {
				compatible = "mediatek,lcd-backlight";
				data = <0x1>;
				led_mode = <0x4>;
				phandle = <0x9b>;
				pwm_config = <0x0 0x1 0x0 0x0 0x0>;
			};

			nfc {
				compatible = "mediatek,nfc-gpio-v2";
				gpio-irq = <0x2>;
				gpio-irq-std = <0xffffffff 0x2 0x0>;
				gpio-rst = <0x15>;
				gpio-rst-std = <0xffffffff 0x15 0x0>;
				phandle = <0xa6>;
			};

			oppo_charger {
				compatible = "mediatek,oppo-charger";
				phandle = <0xa5>;
				pinctrl-0 = <0x15>;
				pinctrl-1 = <0x16>;
				pinctrl-2 = <0x17>;
				pinctrl-3 = <0x18>;
				pinctrl-4 = <0x19>;
				pinctrl-5 = <0x1a>;
				pinctrl-6 = <0x1b>;
				pinctrl-names = "default", "charger_gpio_as_output_low", "charger_gpio_as_output_high", "ship_sleep", "ship_active", "dischg_enable", "dischg_disable";
				qcom,batt_capacity_mah = <0xfb9>;
				qcom,charger_hv_thr = <0x16a8>;
				qcom,charger_lv_thr = <0xd48>;
				qcom,chargerid_switch-gpio = <0xffffffff 0x61 0x0>;
				qcom,check_batt_full_by_sw;
				qcom,chg_ctrl_by_calling;
				qcom,chg_ctrl_by_camera;
				qcom,chg_ctrl_by_lcd;
				qcom,cold_bat_decidegc = <0x14>;
				qcom,cold_vfloat_over_sw_limit = <0xf96>;
				qcom,cold_vfloat_sw_limit = <0xf5a>;
				qcom,cool_bat_decidegc = <0x32>;
				qcom,cool_vfloat_over_sw_limit = <0x115d>;
				qcom,cool_vfloat_over_sw_limit_2nd = <0x112b>;
				qcom,cool_vfloat_sw_limit = <0x1121>;
				qcom,default_iterm_ma = <0xd1>;
				qcom,default_iterm_ma_2nd = <0x12c>;
				qcom,default_normal_vfloat_over_sw_limit = <0x115d>;
				qcom,default_normal_vfloat_over_sw_limit_2nd = <0x115d>;
				qcom,default_normal_vfloat_sw_limit = <0x1121>;
				qcom,default_temp_normal_fastchg_current_ma = <0x898>;
				qcom,default_temp_normal_vfloat_mv = <0x1153>;
				qcom,default_temp_normal_vfloat_mv_2nd = <0x1127>;
				qcom,dischg-gpio = <0xffffffff 0x11 0x0>;
				qcom,external_gauge;
				qcom,ff1_exit_step_ma = <0x258>;
				qcom,ff1_normal_fastchg_ma = <0x5dc>;
				qcom,ff1_warm_exit_step_ma = <0x1f4>;
				qcom,ff1_warm_fastchg_ma = <0x5dc>;
				qcom,ffc2_exit_step_ma = <0xc8>;
				qcom,ffc2_normal_fastchg_ma = <0x44c>;
				qcom,ffc2_normal_vfloat_sw_limit = <0x117b>;
				qcom,ffc2_temp_high_decidegc = <0x190>;
				qcom,ffc2_temp_low_decidegc = <0x78>;
				qcom,ffc2_temp_warm_decidegc = <0x15e>;
				qcom,ffc2_warm_exit_step_ma = <0xc8>;
				qcom,ffc2_warm_fastchg_ma = <0x4b0>;
				qcom,ffc_normal_vfloat_over_sw_limit = <0x11c6>;
				qcom,ffc_normal_vfloat_sw_limit = <0x117b>;
				qcom,ffc_support;
				qcom,ffc_temp_normal_vfloat_mv = <0x11c6>;
				qcom,hot_bat_decidegc = <0x212>;
				qcom,input_current_calling_ma = <0x5dc>;
				qcom,input_current_camera_ma = <0x4b0>;
				qcom,input_current_cdp_ma = <0x5dc>;
				qcom,input_current_charger_ma = <0x7d0>;
				qcom,input_current_led_ma = <0x4b0>;
				qcom,input_current_led_ma_forcmcc = <0x1f4>;
				qcom,input_current_led_ma_high = <0x4b0>;
				qcom,input_current_led_ma_normal = <0x7d0>;
				qcom,input_current_led_ma_warm = <0x5dc>;
				qcom,input_current_usb_ma = <0x1f4>;
				qcom,iterm_disabled = <0x0>;
				qcom,iterm_ma = <0xd1>;
				qcom,iterm_ma_2nd = <0x12c>;
				qcom,led_high_bat_decidegc = <0x172>;
				qcom,led_warm_bat_decidegc = <0x15e>;
				qcom,little_cold_bat_decidegc = <0x0>;
				qcom,little_cold_vfloat_over_sw_limit = <0x115d>;
				qcom,little_cold_vfloat_over_sw_limit_2nd = <0x112b>;
				qcom,little_cold_vfloat_sw_limit = <0x1121>;
				qcom,little_cool_bat_decidegc = <0x78>;
				qcom,little_cool_vfloat_over_sw_limit = <0x115d>;
				qcom,little_cool_vfloat_over_sw_limit_2nd = <0x112b>;
				qcom,little_cool_vfloat_sw_limit = <0x1121>;
				qcom,max_chg_time_sec = <0x8ca0>;
				qcom,non_normal_vterm_hw_inc = <0xd>;
				qcom,non_standard_fastchg_current_ma = <0x200>;
				qcom,non_standard_vfloat_mv = <0xf8c>;
				qcom,non_standard_vfloat_over_sw_limit = <0xf96>;
				qcom,non_standard_vfloat_sw_limit = <0xf5a>;
				qcom,normal_bat_decidegc = <0xa0>;
				qcom,normal_vfloat_over_sw_limit = <0x115d>;
				qcom,normal_vfloat_over_sw_limit_2nd = <0x115d>;
				qcom,normal_vfloat_sw_limit = <0x1121>;
				qcom,normal_vterm_hw_inc = <0xd>;
				qcom,pd_input_current_charger_ma = <0xbb8>;
				qcom,pd_temp_cool_fastchg_current_ma_high = <0x9f6>;
				qcom,pd_temp_cool_fastchg_current_ma_low = <0x73a>;
				qcom,pd_temp_little_cold_fastchg_current_ma_high = <0x73a>;
				qcom,pd_temp_little_cold_fastchg_current_ma_low = <0x44c>;
				qcom,pd_temp_little_cool_fastchg_current_ma = <0xce4>;
				qcom,pd_temp_normal_fastchg_current_ma = <0xce4>;
				qcom,pd_temp_warm_fastchg_current_ma = <0x44c>;
				qcom,recharge-mv = <0x64>;
				qcom,recharge-mv_2nd = <0x79>;
				qcom,removed_bat_decidegc = <0xbe>;
				qcom,ship-gpio = <0xffffffff 0x9b 0x0>;
				qcom,short_c_bat_cv_mv = <0x10ea>;
				qcom,short_c_bat_fastchg_current_ma = <0x200>;
				qcom,short_c_bat_vfloat_mv = <0xed8>;
				qcom,short_c_bat_vfloat_sw_limit = <0xea6>;
				qcom,sw_vfloat_over_protect_enable;
				qcom,temp_cold_fastchg_current_ma = <0x168>;
				qcom,temp_cold_vfloat_mv = <0xf8c>;
				qcom,temp_cool_fastchg_current_ma_high = <0x898>;
				qcom,temp_cool_fastchg_current_ma_low = <0x73a>;
				qcom,temp_cool_vfloat_mv = <0x1153>;
				qcom,temp_cool_vfloat_mv_2nd = <0x1127>;
				qcom,temp_little_cold_fastchg_current_ma = <0x44c>;
				qcom,temp_little_cold_fastchg_current_ma_high = <0x73a>;
				qcom,temp_little_cold_fastchg_current_ma_low = <0x44c>;
				qcom,temp_little_cold_vfloat_mv = <0x1153>;
				qcom,temp_little_cold_vfloat_mv_2nd = <0x1127>;
				qcom,temp_little_cool_fastchg_current_ma = <0x898>;
				qcom,temp_little_cool_vfloat_mv = <0x1153>;
				qcom,temp_little_cool_vfloat_mv_2nd = <0x1127>;
				qcom,temp_normal_fastchg_current_ma = <0x898>;
				qcom,temp_normal_vfloat_mv = <0x1153>;
				qcom,temp_normal_vfloat_mv_2nd = <0x1127>;
				qcom,temp_warm_fastchg_current_ma = <0x44c>;
				qcom,temp_warm_fastchg_current_ma_led_on = <0x1f4>;
				qcom,temp_warm_vfloat_mv = <0x1022>;
				qcom,vbatt_full_thr = <0x1162>;
				qcom,vbatt_hv_thr = <0x11c6>;
				qcom,vbatt_num = <0x1>;
				qcom,vbatt_power_off = <0xce4>;
				qcom,vbatt_soc_1 = <0xd52>;
				qcom,vfloat_step_mv = <0xa>;
				qcom,vooc_project = <0x1>;
				qcom,warm_bat_decidegc = <0x1c2>;
				qcom,warm_vfloat_over_sw_limit = <0x102c>;
				qcom,warm_vfloat_sw_limit = <0xff0>;
			};

			oppo_devinfo {
				Hw,main_hwid_5 = <0xffffffff 0x12 0x0>;
				Hw,main_hwid_6 = <0xffffffff 0x50 0x0>;
				Hw,sub_hwid_1 = <0xffffffff 0x3a 0x0>;
				Hw,sub_hwid_2 = <0xffffffff 0x9d 0x0>;
				compatible = "oppo, device_info";
				phandle = <0xa2>;
				pinctrl-0 = <0xe>;
				pinctrl-1 = <0xf 0x10>;
				pinctrl-2 = <0x11 0x12>;
				pinctrl-3 = <0x13>;
				pinctrl-4 = <0x14>;
				pinctrl-names = "default", "hw_sub_id_sleep", "hw_sub_id_active", "hw_main_id5_active", "hw_main_id6_active";
			};

			oppo_project {
				compatible = "oppo,oppo_project";
				phandle = <0x9e>;
			};

			oppo_sensor {
				phandle = <0xa1>;
			};

			usb_c_pinctrl {
				compatible = "mediatek,usb_c_pinctrl";
				phandle = <0x9d>;
				pinctrl-0 = <0x1>;
				pinctrl-1 = <0x2>;
				pinctrl-10 = <0xb>;
				pinctrl-11 = <0xc>;
				pinctrl-12 = <0xd>;
				pinctrl-2 = <0x3>;
				pinctrl-3 = <0x4>;
				pinctrl-4 = <0x5>;
				pinctrl-5 = <0x6>;
				pinctrl-6 = <0x7>;
				pinctrl-7 = <0x8>;
				pinctrl-8 = <0x9>;
				pinctrl-9 = <0xa>;
				pinctrl-names = "usb_default", "redrv_c1_init", "redrv_c1_low", "redrv_c1_hiz", "redrv_c1_high", "redrv_c2_init", "redrv_c2_low", "redrv_c2_hiz", "redrv_c2_high", "switch_sel1", "switch_sel2", "switch_enable", "switch_disable";
				status = "okay";

				usb_switch-data {
					c1_pin_num = <0x12>;
					c1_pin_val = <0x2>;
					c2_pin_num = <0x11>;
					c2_pin_val = <0x1>;
					en_pin_num = <0x0>;
					en_pin_val = <0x0>;
					sel_pin_num = <0xb1>;
					sel_pin_val = <0x1>;
				};
			};

			vibrator@0 {
				compatible = "mediatek,vibrator";
				phandle = <0x9c>;
				vib_limit = <0x0>;
				vib_timer = <0x1e>;
				vib_vol = <0xb>;
			};

			vooc_ap_data {
				compatible = "mediatek, VOOC_AP_DATA-eint";
				interrupts = <0x1a 0x2 0x1a 0x0>;
				phandle = <0xa3>;
			};

			vooc_ap_data_new_function {
				compatible = "mediatek, VOOC_EINT_NEW_FUNCTION";
				phandle = <0xa4>;
			};
		};
	};

	fragment@20 {
		target = <0xffffffff>;

		__overlay__ {
			pinctrl-0 = <0x42>;
			pinctrl-1 = <0x43>;
			pinctrl-2 = <0x44>;
			pinctrl-3 = <0x45>;
			pinctrl-4 = <0x46>;
			pinctrl-5 = <0x47>;
			pinctrl-6 = <0x48>;
			pinctrl-names = "uart0_gpio_default", "uart0_rx_set", "uart0_rx_clear", "uart0_tx_set", "uart0_tx_clear", "uart0_rx_gpio", "uart0_tx_gpio";
			status = "okay";
		};
	};

	fragment@21 {
		target = <0xffffffff>;

		__overlay__ {

			uart0_rx_clear@gpio95 {
				phandle = <0x44>;

				pins_cmd_dat {
					output-high;
					pinmux = <0x5f00>;
					slew-rate = <0x1>;
				};
			};

			uart0_rx_gpio@gpio95 {
				phandle = <0x47>;

				pins_cmd_dat {
					bias-disable;
					input-enable;
					pinmux = <0x5f00>;
					slew-rate = <0x0>;
				};
			};

			uart0_rx_set@gpio95 {
				phandle = <0x43>;

				pins_cmd_dat {
					pinmux = <0x5f01>;
				};
			};

			uart0_tx_clear@gpio96 {
				phandle = <0x46>;

				pins_cmd_dat {
					output-high;
					pinmux = <0x6000>;
					slew-rate = <0x1>;
				};
			};

			uart0_tx_gpio@gpio96 {
				phandle = <0x48>;

				pins_cmd_dat {
					bias-disable;
					input-enable;
					pinmux = <0x6000>;
					slew-rate = <0x0>;
				};
			};

			uart0_tx_set@gpio96 {
				phandle = <0x45>;

				pins_cmd_dat {
					pinmux = <0x6001>;
				};
			};

			uart0gpiodefault {
				phandle = <0x42>;
			};
		};
	};

	fragment@22 {
		target = <0xffffffff>;

		__overlay__ {
			pinctrl-0 = <0x49>;
			pinctrl-1 = <0x4a>;
			pinctrl-names = "irtx_gpio_led_default", "irtx_gpio_led_set";
			status = "okay";
		};
	};

	fragment@23 {
		target = <0xffffffff>;

		__overlay__ {

			irtx_gpio_led_def@gpio90 {
				phandle = <0x49>;

				pins_cmd_dat {
					bias-disable;
					input-schmitt-enable = <0x0>;
					output-low;
					pinmux = <0x5a00>;
					slew-rate = <0x1>;
				};
			};

			irtx_gpio_led_set@gpio90 {
				phandle = <0x4a>;

				pins_cmd_dat {
					output-high;
					pinmux = <0x5a01>;
					slew-rate = <0x1>;
				};
			};
		};
	};

	fragment@24 {
		target = <0xffffffff>;

		__overlay__ {
			mt6370,intr_gpio = <0xffffffff 0x5b 0x0>;
			mt6370,intr_gpio_num = <0x5b>;
		};
	};

	fragment@25 {
		target = <0xffffffff>;

		__overlay__ {
			mt-tcpc,role_def = <0x0>;
			mt6370pd,intr_gpio = <0xffffffff 0x29 0x0>;
			mt6370pd,intr_gpio_num = <0x29>;
		};
	};

	fragment@26 {
		target = <0xffffffff>;

		__overlay__ {
			status = "disabled";
		};
	};

	fragment@27 {
		target = <0xffffffff>;

		__overlay__ {

			c1_high {
				phandle = <0x5>;
			};

			c1_highz {
				phandle = <0x4>;
			};

			c1_init {
				phandle = <0x2>;
			};

			c1_low {
				phandle = <0x3>;
			};

			c2_high {
				phandle = <0x9>;
			};

			c2_highz {
				phandle = <0x8>;
			};

			c2_init {
				phandle = <0x6>;
			};

			c2_low {
				phandle = <0x7>;
			};

			u3_sw_dis {
				phandle = <0xd>;
			};

			u3_sw_en {
				phandle = <0xc>;
			};

			u3_sw_sel1 {
				phandle = <0xa>;
			};

			u3_sw_sel2 {
				phandle = <0xb>;
			};

			usb_default {
				phandle = <0x1>;
			};
		};
	};

	fragment@28 {
		target = <0xffffffff>;

		__overlay__ {
			keypad,volume-down = <0xffffffff 0x5e 0x0>;
			keypad,volume-up = <0xffffffff 0x14 0x0>;
			pinctrl-0 = <0x4b>;
			pinctrl-1 = <0x4c>;
			pinctrl-names = "volume_up_as_int", "volume_down_as_int";
			status = "okay";
		};
	};

	fragment@29 {
		target = <0xffffffff>;

		__overlay__ {

			volume_down@0 {
				phandle = <0x4c>;

				pins_cmd_dat {
					bias-pull-up = <0x0>;
					input-enable;
					pinmux = <0x5e00>;
					slew-rate = <0x0>;
				};
			};

			volume_up@0 {
				phandle = <0x4b>;

				pins_cmd_dat {
					bias-pull-up = <0x0>;
					input-enable;
					pinmux = <0x1400>;
					slew-rate = <0x0>;
				};
			};
		};
	};

	fragment@3 {
		target = <0xffffffff>;

		__overlay__ {

			phy_tuning {
				compatible = "mediatek,phy_tuning";
				u2_enhance = <0x2>;
				u2_term_ref = <0x7>;
				u2_vrt_ref = <0x7>;
			};
		};
	};

	fragment@30 {
		target = <0xffffffff>;

		__overlay__ {
			pinctrl-0 = <0x4d>;
			pinctrl-1 = <0x4e>;
			pinctrl-names = "msdc1_on", "msdc1_off";
			status = "okay";
		};
	};

	fragment@31 {
		target = <0xffffffff>;

		__overlay__ {

			sd0@0 {
				phandle = <0x4d>;

				pins_cmd_dat {
					output-high;
					pinmux = <0x5a00>;
					slew-rate = <0x1>;
				};
			};

			sd0@1 {
				phandle = <0x4e>;

				pins_cmd_dat {
					output-low;
					pinmux = <0x5a00>;
					slew-rate = <0x1>;
				};
			};
		};
	};

	fragment@32 {
		target = <0xffffffff>;

		__overlay__ {
			algorithm_name = "DualSwitchCharging";
			chg1_ta_ac_charger_current = <0x1e8480>;
			chg2_ta_ac_charger_current = <0x1e8480>;
		};
	};

	fragment@33 {
		target = <0xffffffff>;

		__overlay__ {

			charger_gpio_as_output_high {
				phandle = <0x17>;

				pins_cmd_dat {
					output-high;
					pinmux = <0x6100>;
					slew-rate = <0x1>;
				};
			};

			charger_gpio_as_output_low {
				phandle = <0x16>;

				pins_cmd_dat {
					output-low;
					pinmux = <0x6100>;
					slew-rate = <0x1>;
				};
			};

			dischg_disable {
				phandle = <0x1b>;

				pins_cmd_dat {
					bias-pull-down = <0x0>;
					output-low;
					pinmux = <0x1100>;
					slew-rate = <0x1>;
				};
			};

			dischg_enable {
				phandle = <0x1a>;

				pins_cmd_dat {
					bias-pull-up = <0x0>;
					output-high;
					pinmux = <0x1100>;
					slew-rate = <0x1>;
				};
			};

			eint0default {
				phandle = <0x15>;
			};

			ship_active {
				phandle = <0x19>;

				pins_cmd_dat {
					output-high;
					pinmux = <0x9b00>;
					slew-rate = <0x1>;
				};
			};

			ship_sleep {
				phandle = <0x18>;

				pins_cmd_dat {
					output-low;
					pinmux = <0x9b00>;
					slew-rate = <0x1>;
				};
			};

			shortc_active {
				phandle = <0xa8>;

				pins_cmd_dat {
					bias-pull-up;
					input-enable;
					pinmux = <0x4d00>;
					slew-rate = <0x0>;
				};
			};
		};
	};

	fragment@34 {
		target = <0xffffffff>;

		__overlay__ {

			bq27541-battery@55 {
				compatible = "oppo,bq27541-battery";
				qcom,modify-soc-smooth;
				reg = <0x55 0x0>;
				status = "okay";
			};

			oppo_short-ic@58 {
				compatible = "oppo,oppo_short-ic";
				qcom,modify-soc-smooth;
				reg = <0x58>;
				status = "okay";
			};

			rk826_fastcg@0a {
				compatible = "oppo,rk826-fastcg";
				pinctrl-0 = <0x4f>;
				pinctrl-1 = <0x50>;
				pinctrl-10 = <0x55>;
				pinctrl-11 = <0x56>;
				pinctrl-12 = <0x57>;
				pinctrl-13 = <0x58>;
				pinctrl-2 = <0x4f>;
				pinctrl-3 = <0x50>;
				pinctrl-4 = <0x4f>;
				pinctrl-5 = <0x50>;
				pinctrl-6 = <0x51>;
				pinctrl-7 = <0x52>;
				pinctrl-8 = <0x53>;
				pinctrl-9 = <0x54>;
				pinctrl-names = "switch1_act_switch2_act", "switch1_sleep_switch2_sleep", "switch1_act_switch3_act", "switch1_sleep_switch3_sleep", "switch1_act_switch2_sleep", "switch1_sleep_switch2_act", "clock_active", "clock_sleep", "data_active", "data_sleep", "reset_active", "reset_sleep", "charging_switch1_ctr1_active", "charging_switch1_ctr1_sleep";
				qcom,charging_clock-gpio = <0xffffffff 0x19 0x0>;
				qcom,charging_data-gpio = <0xffffffff 0x1a 0x0>;
				qcom,charging_reset-gpio = <0xffffffff 0xa0 0x0>;
				qcom,charging_switch1-gpio = <0xffffffff 0xa6 0x0>;
				qcom,charging_switch1_ctr1-gpio = <0xffffffff 0x7f 0x0>;
				qcom,oppo_batt_4400mv;
				qcom,vooc-fw-type = <0x1>;
				qcom,vooc-low-temp = <0x78>;
				qcom,vooc_fw_update_newmethod;
				reg = <0xa 0x0>;
				status = "okay";
			};

			stm8s_fastcg@26 {
				compatible = "oppo,stm8s-fastcg";
				pinctrl-0 = <0x4f>;
				pinctrl-1 = <0x50>;
				pinctrl-10 = <0x55>;
				pinctrl-11 = <0x56>;
				pinctrl-2 = <0x4f>;
				pinctrl-3 = <0x50>;
				pinctrl-4 = <0x4f>;
				pinctrl-5 = <0x50>;
				pinctrl-6 = <0x51>;
				pinctrl-7 = <0x52>;
				pinctrl-8 = <0x53>;
				pinctrl-9 = <0x54>;
				pinctrl-names = "switch1_act_switch2_act", "switch1_sleep_switch2_sleep", "switch1_act_switch3_act", "switch1_sleep_switch3_sleep", "switch1_act_switch2_sleep", "switch1_sleep_switch2_act", "clock_active", "clock_sleep", "data_active", "data_sleep", "reset_active", "reset_sleep";
				qcom,charging_clock-gpio = <0xffffffff 0x19 0x0>;
				qcom,charging_data-gpio = <0xffffffff 0x1a 0x0>;
				qcom,charging_reset-gpio = <0xffffffff 0xa0 0x0>;
				qcom,charging_switch1-gpio = <0xffffffff 0xa6 0x0>;
				qcom,oppo_batt_4400mv;
				qcom,vooc-fw-type = <0xa>;
				qcom,vooc-low-temp = <0x78>;
				qcom,vooc_fw_update_newmethod;
				reg = <0x26 0x0>;
				status = "okay";
			};
		};
	};

	fragment@35 {
		target = <0xffffffff>;

		__overlay__ {

			charging_clock_active {
				phandle = <0x51>;

				pins_cmd_dat {
					bias-pull-up = <0x0>;
					pinmux = <0x1900>;
					slew-rate = <0x0>;
				};
			};

			charging_clock_sleep {
				phandle = <0x52>;

				pins_cmd_dat {
					bias-pull-down = <0x0>;
					pinmux = <0x1900>;
					slew-rate = <0x0>;
				};
			};

			charging_data_active {
				phandle = <0x53>;

				pins_cmd_dat {
					bias-pull-up = <0x0>;
					pinmux = <0x1a00>;
					slew-rate = <0x0>;
				};
			};

			charging_data_sleep {
				phandle = <0x54>;

				pins_cmd_dat {
					bias-pull-down = <0x0>;
					pinmux = <0x1a00>;
					slew-rate = <0x0>;
				};
			};

			charging_reset_active {
				phandle = <0x55>;

				pins_cmd_dat {
					output-high;
					pinmux = <0xa000>;
					slew-rate = <0x1>;
				};
			};

			charging_reset_sleep {
				phandle = <0x56>;

				pins_cmd_dat {
					output-low;
					pinmux = <0xa000>;
					slew-rate = <0x1>;
				};
			};

			charging_switch1_active {
				phandle = <0x4f>;

				pins_cmd_dat {
					output-high;
					pinmux = <0xa600>;
					slew-rate = <0x1>;
				};
			};

			charging_switch1_ctr1_active {
				phandle = <0x57>;

				pins_cmd_dat {
					output-high;
					pinmux = <0x7f00>;
					slew-rate = <0x1>;
				};
			};

			charging_switch1_ctr1_sleep {
				phandle = <0x58>;

				pins_cmd_dat {
					output-low;
					pinmux = <0x7f00>;
					slew-rate = <0x1>;
				};
			};

			charging_switch1_sleep {
				phandle = <0x50>;

				pins_cmd_dat {
					output-low;
					pinmux = <0xa600>;
					slew-rate = <0x1>;
				};
			};
		};
	};

	fragment@36 {
		target = <0xffffffff>;

		__overlay__ {

			cam0@0 {
				phandle = <0x5a>;

				pins_cmd_dat {
					output-low;
					pinmux = <0x6600>;
					slew-rate = <0x1>;
				};
			};

			cam0@1 {
				phandle = <0x5b>;

				pins_cmd_dat {
					output-high;
					pinmux = <0x6600>;
					slew-rate = <0x1>;
				};
			};

			cam0@vcam0 {
				phandle = <0x64>;

				pins_cmd_dat {
					output-low;
					pinmux = <0xb300>;
					slew-rate = <0x1>;
				};
			};

			cam0@vcam1 {
				phandle = <0x65>;

				pins_cmd_dat {
					output-high;
					pinmux = <0xb300>;
					slew-rate = <0x1>;
				};
			};

			cam1@0 {
				phandle = <0x5c>;

				pins_cmd_dat {
					output-low;
					pinmux = <0x6d00>;
					slew-rate = <0x1>;
				};
			};

			cam1@1 {
				phandle = <0x5d>;

				pins_cmd_dat {
					output-high;
					pinmux = <0x6d00>;
					slew-rate = <0x1>;
				};
			};

			cam1@vcamd0 {
				phandle = <0x66>;

				pins_cmd_dat {
					output-low;
					pinmux = <0xb300>;
					slew-rate = <0x1>;
				};
			};

			cam1@vcamd1 {
				phandle = <0x67>;

				pins_cmd_dat {
					output-high;
					pinmux = <0xb300>;
					slew-rate = <0x1>;
				};
			};

			cam2@0 {
				phandle = <0x5e>;

				pins_cmd_dat {
					output-low;
					pinmux = <0x6200>;
					slew-rate = <0x1>;
				};
			};

			cam2@1 {
				phandle = <0x5f>;

				pins_cmd_dat {
					output-high;
					pinmux = <0x6200>;
					slew-rate = <0x1>;
				};
			};

			cam3@0 {
				phandle = <0x60>;

				pins_cmd_dat {
					output-low;
					pinmux = <0xb100>;
					slew-rate = <0x1>;
				};
			};

			cam3@1 {
				phandle = <0x61>;

				pins_cmd_dat {
					output-high;
					pinmux = <0xb100>;
					slew-rate = <0x1>;
				};
			};

			cam4@0 {
				phandle = <0x62>;

				pins_cmd_dat {
					output-low;
					pinmux = <0x6500>;
					slew-rate = <0x1>;
				};
			};

			cam4@1 {
				phandle = <0x63>;

				pins_cmd_dat {
					output-high;
					pinmux = <0x6500>;
					slew-rate = <0x1>;
				};
			};

			camdefault {
				phandle = <0x59>;
			};

			camera_mipi_switch_output_high@gpio76 {
				phandle = <0x82>;

				pins_cmd_dat {
					output-high;
					pinmux = <0x4c00>;
				};
			};

			camera_mipi_switch_output_low@gpio76 {
				phandle = <0x81>;

				pins_cmd_dat {
					output-low;
					pinmux = <0x4c00>;
				};
			};

			camera_pins_cam0_mclk_2ma {
				phandle = <0x69>;

				pins_cmd_dat {
					drive-strength = <0x0>;
					pinmux = <0x6401>;
				};
			};

			camera_pins_cam0_mclk_4ma {
				phandle = <0x6a>;

				pins_cmd_dat {
					drive-strength = <0x1>;
					pinmux = <0x6401>;
				};
			};

			camera_pins_cam0_mclk_6ma {
				phandle = <0x6b>;

				pins_cmd_dat {
					drive-strength = <0x2>;
					pinmux = <0x6401>;
				};
			};

			camera_pins_cam0_mclk_8ma {
				phandle = <0x6c>;

				pins_cmd_dat {
					drive-strength = <0x3>;
					pinmux = <0x6401>;
				};
			};

			camera_pins_cam0_mclk_off {
				phandle = <0x68>;

				pins_cmd_dat {
					drive-strength = <0x1>;
					pinmux = <0x6400>;
				};
			};

			camera_pins_cam1_mclk_2ma {
				phandle = <0x6e>;

				pins_cmd_dat {
					drive-strength = <0x0>;
					pinmux = <0x6c01>;
				};
			};

			camera_pins_cam1_mclk_4ma {
				phandle = <0x6f>;

				pins_cmd_dat {
					drive-strength = <0x1>;
					pinmux = <0x6c01>;
				};
			};

			camera_pins_cam1_mclk_6ma {
				phandle = <0x70>;

				pins_cmd_dat {
					drive-strength = <0x2>;
					pinmux = <0x6c01>;
				};
			};

			camera_pins_cam1_mclk_8ma {
				phandle = <0x71>;

				pins_cmd_dat {
					drive-strength = <0x3>;
					pinmux = <0x6c01>;
				};
			};

			camera_pins_cam1_mclk_off {
				phandle = <0x6d>;

				pins_cmd_dat {
					drive-strength = <0x1>;
					pinmux = <0x6c00>;
				};
			};

			camera_pins_cam2_mclk_2ma {
				phandle = <0x73>;

				pins_cmd_dat {
					drive-strength = <0x0>;
					pinmux = <0xa502>;
				};
			};

			camera_pins_cam2_mclk_4ma {
				phandle = <0x74>;

				pins_cmd_dat {
					drive-strength = <0x1>;
					pinmux = <0xa502>;
				};
			};

			camera_pins_cam2_mclk_6ma {
				phandle = <0x75>;

				pins_cmd_dat {
					drive-strength = <0x2>;
					pinmux = <0xa502>;
				};
			};

			camera_pins_cam2_mclk_8ma {
				phandle = <0x76>;

				pins_cmd_dat {
					drive-strength = <0x3>;
					pinmux = <0xa502>;
				};
			};

			camera_pins_cam2_mclk_off {
				phandle = <0x72>;

				pins_cmd_dat {
					drive-strength = <0x1>;
					pinmux = <0xa500>;
				};
			};

			camera_pins_cam3_mclk_2ma {
				phandle = <0x78>;

				pins_cmd_dat {
					drive-strength = <0x0>;
					pinmux = <0x6f01>;
				};
			};

			camera_pins_cam3_mclk_4ma {
				phandle = <0x79>;

				pins_cmd_dat {
					drive-strength = <0x1>;
					pinmux = <0x6f01>;
				};
			};

			camera_pins_cam3_mclk_6ma {
				phandle = <0x7a>;

				pins_cmd_dat {
					drive-strength = <0x2>;
					pinmux = <0x6f01>;
				};
			};

			camera_pins_cam3_mclk_8ma {
				phandle = <0x7b>;

				pins_cmd_dat {
					drive-strength = <0x3>;
					pinmux = <0x6f01>;
				};
			};

			camera_pins_cam3_mclk_off {
				phandle = <0x77>;

				pins_cmd_dat {
					drive-strength = <0x1>;
					pinmux = <0x6f00>;
				};
			};

			camera_pins_cam4_mclk_2ma {
				phandle = <0x7d>;

				pins_cmd_dat {
					drive-strength = <0x0>;
					pinmux = <0x6301>;
				};
			};

			camera_pins_cam4_mclk_4ma {
				phandle = <0x7e>;

				pins_cmd_dat {
					drive-strength = <0x1>;
					pinmux = <0x6301>;
				};
			};

			camera_pins_cam4_mclk_6ma {
				phandle = <0x7f>;

				pins_cmd_dat {
					drive-strength = <0x2>;
					pinmux = <0x6301>;
				};
			};

			camera_pins_cam4_mclk_8ma {
				phandle = <0x80>;

				pins_cmd_dat {
					drive-strength = <0x3>;
					pinmux = <0x6301>;
				};
			};

			camera_pins_cam4_mclk_off {
				phandle = <0x7c>;

				pins_cmd_dat {
					drive-strength = <0x1>;
					pinmux = <0x6300>;
				};
			};
		};
	};

	fragment@37 {
		target = <0xffffffff>;

		__overlay__ {
			cam0_enable_sensor = "s5kgm1sp_mipi_raw";
			cam0_vcama-supply = <0xffffffff>;
			cam0_vcamio-supply = <0xffffffff>;
			cam1_enable_sensor = "s5k3p9sp_mipi_raw";
			cam1_vcama-supply = <0xffffffff>;
			cam1_vcamio-supply = <0xffffffff>;
			cam2_enable_sensor = "hi846_mipi_raw3";
			cam2_vcama-supply = <0xffffffff>;
			cam2_vcamd-supply = <0xffffffff>;
			cam2_vcamio-supply = <0xffffffff>;
			cam3_enable_sensor = "ov02a10_mipi_raw2 gc02m0_mipi_mono1";
			cam3_vcama-supply = <0xffffffff>;
			cam3_vcamio-supply = <0xffffffff>;
			cam4_enable_sensor = "ov02a10_mipi_raw1 gc02m0_mipi_mono";
			cam4_vcama-supply = <0xffffffff>;
			cam4_vcamio-supply = <0xffffffff>;
			pinctrl-0 = <0x59>;
			pinctrl-1 = <0x5a>;
			pinctrl-10 = <0x63>;
			pinctrl-11 = <0x64>;
			pinctrl-12 = <0x65>;
			pinctrl-13 = <0x66>;
			pinctrl-14 = <0x67>;
			pinctrl-15 = <0x68>;
			pinctrl-16 = <0x69>;
			pinctrl-17 = <0x6a>;
			pinctrl-18 = <0x6b>;
			pinctrl-19 = <0x6c>;
			pinctrl-2 = <0x5b>;
			pinctrl-20 = <0x6d>;
			pinctrl-21 = <0x6e>;
			pinctrl-22 = <0x6f>;
			pinctrl-23 = <0x70>;
			pinctrl-24 = <0x71>;
			pinctrl-25 = <0x72>;
			pinctrl-26 = <0x73>;
			pinctrl-27 = <0x74>;
			pinctrl-28 = <0x75>;
			pinctrl-29 = <0x76>;
			pinctrl-3 = <0x5c>;
			pinctrl-30 = <0x77>;
			pinctrl-31 = <0x78>;
			pinctrl-32 = <0x79>;
			pinctrl-33 = <0x7a>;
			pinctrl-34 = <0x7b>;
			pinctrl-35 = <0x7c>;
			pinctrl-36 = <0x7d>;
			pinctrl-37 = <0x7e>;
			pinctrl-38 = <0x7f>;
			pinctrl-39 = <0x80>;
			pinctrl-4 = <0x5d>;
			pinctrl-40 = <0x81>;
			pinctrl-41 = <0x82>;
			pinctrl-5 = <0x5e>;
			pinctrl-6 = <0x5f>;
			pinctrl-7 = <0x60>;
			pinctrl-8 = <0x61>;
			pinctrl-9 = <0x62>;
			pinctrl-names = "default", "cam0_rst0", "cam0_rst1", "cam1_rst0", "cam1_rst1", "cam2_rst0", "cam2_rst1", "cam3_rst0", "cam3_rst1", "cam4_rst0", "cam4_rst1", "cam0_ldo_vcamd_0", "cam0_ldo_vcamd_1", "cam1_ldo_vcamd_0", "cam1_ldo_vcamd_1", "cam0_mclk_off", "cam0_mclk_2mA", "cam0_mclk_4mA", "cam0_mclk_6mA", "cam0_mclk_8mA", "cam1_mclk_off", "cam1_mclk_2mA", "cam1_mclk_4mA", "cam1_mclk_6mA", "cam1_mclk_8mA", "cam2_mclk_off", "cam2_mclk_2mA", "cam2_mclk_4mA", "cam2_mclk_6mA", "cam2_mclk_8mA", "cam3_mclk_off", "cam3_mclk_2mA", "cam3_mclk_4mA", "cam3_mclk_6mA", "cam3_mclk_8mA", "cam4_mclk_off", "cam4_mclk_2mA", "cam4_mclk_4mA", "cam4_mclk_6mA", "cam4_mclk_8mA", "cam_mipi_switch_en_0", "cam_mipi_switch_en_1";
			status = "okay";
		};
	};

	fragment@38 {
		target = <0xffffffff>;

		__overlay__ {

			fpc_irq_default {
				phandle = <0x84>;

				pins_cmd_dat {
					bias-pull-up = <0x0>;
					pins = <0xa00>;
					slew-rate = <0x0>;
				};
			};

			fpc_pwr_default {
				phandle = <0x85>;

				pins_cmd_dat {
					bias-pull-up = <0x0>;
					output-high;
					pins = <0xb000>;
					slew-rate = <0x1>;
				};
			};

			fpc_reset_default {
				phandle = <0x83>;

				pins_cmd_dat {
					output-low;
					pins = <0x4f00>;
					slew-rate = <0x1>;
				};
			};

			gpio_fpc_cs_func {
				phandle = <0x86>;

				pins_cmd_dat {
					drive-strength = <0x3>;
					pins = <0x5601>;
				};
			};
		};
	};

	fragment@39 {
		target = <0xffffffff>;

		__overlay__ {
			fpc,gpio_cs = <0xffffffff 0x56 0x0>;
			fpc,irq-gpio = <0xffffffff 0xa 0x0>;
			fpc,reset-gpio = <0xffffffff 0x4f 0x0>;
			fpc,vdd-en = <0xffffffff 0xb0 0x0>;
			pinctrl-0 = <0x83 0x84 0x85>;
			pinctrl-1 = <0x86>;
			pinctrl-names = "default", "fpc_cs_func";
			status = "okay";
		};
	};

	fragment@4 {
		target = <0xffffffff>;

		__overlay__ {
			core_1 = "enable";
			scp_sramSize = <0x80000>;
		};
	};

	fragment@40 {
		target = <0xffffffff>;

		__overlay__ {

			gpio_goodix_clk_6mA {
				phandle = <0x89>;

				pins_cmd_dat {
					drive-strength = <0x2>;
					pinmux = <0x5801>;
				};
			};

			gpio_goodix_clk_6mA_pulllow {
				phandle = <0x8e>;

				pins_cmd_dat {
					output-low;
					pinmux = <0x5800>;
					slew-rate = <0x1>;
				};
			};

			gpio_goodix_cs_6mA {
				phandle = <0x8c>;

				pins_cmd_dat {
					drive-strength = <0x2>;
					pinmux = <0x5601>;
				};
			};

			gpio_goodix_cs_6mA_pulllow {
				phandle = <0x91>;

				pins_cmd_dat {
					output-low;
					pinmux = <0x5600>;
					slew-rate = <0x1>;
				};
			};

			gpio_goodix_cs_func {
				phandle = <0x8d>;

				pins_cmd_dat {
					drive-strength = <0x2>;
					pinmux = <0x5601>;
				};
			};

			gpio_goodix_irq_default {
				phandle = <0x87>;

				pins_cmd_dat {
					bias-pull-down;
					pinmux = <0xa00>;
					slew-rate = <0x0>;
				};
			};

			gpio_goodix_miso_6mA {
				phandle = <0x8b>;

				pins_cmd_dat {
					drive-strength = <0x3>;
					pinmux = <0x5501>;
				};
			};

			gpio_goodix_miso_6mA_pulllow {
				phandle = <0x90>;

				pins_cmd_dat {
					output-low;
					pinmux = <0x5500>;
					slew-rate = <0x1>;
				};
			};

			gpio_goodix_mosi_6mA {
				phandle = <0x8a>;

				pins_cmd_dat {
					drive-strength = <0x2>;
					pinmux = <0x5701>;
				};
			};

			gpio_goodix_mosi_6mA_pulllow {
				phandle = <0x8f>;

				pins_cmd_dat {
					output-low;
					pinmux = <0x5700>;
					slew-rate = <0x1>;
				};
			};

			gpio_goodix_reset_default {
				phandle = <0x88>;

				pins_cmd_dat {
					output-low;
					pinmux = <0x2b00>;
					slew-rate = <0x1>;
				};
			};
		};
	};

	fragment@41 {
		target = <0xffffffff>;

		__overlay__ {
			#address-cells = <0x1>;
			#size-cells = <0x0>;
			status = "okay";

			fingerprint@0 {
				compatible = "oppo,oppo_fp";
				phandle = <0xa9>;
				pw_en_gpio = <0xffffffff 0xb0 0x0>;
				reg = <0x0>;
				spi-id = <0x0>;
				spi-irq = <0xa>;
				spi-max-frequency = <0x7a1200>;
				spi-reg = <0xa7ffd0>;
				status = "okay";
				vddio_en = <0xffffffff 0x97 0x0>;

				power_source_1 {
					delay-time = <0x0>;
					power-mode = <0x2>;
					power-name = "pw_en_gpio";
					poweron-level = <0x1>;
				};

				power_source_2 {
					delay-time = <0x0>;
					power-mode = <0x2>;
					power-name = "vddio_en";
					poweron-level = <0x0>;
				};
			};
		};
	};

	fragment@42 {
		target = <0xffffffff>;

		__overlay__ {
			goodix,gpio_cs = <0xffffffff 0x56 0x0>;
			goodix,gpio_irq = <0xffffffff 0xa 0x0>;
			goodix,gpio_reset = <0xffffffff 0x2b 0x0>;
			goodix,pw_en = <0xffffffff 0xb0 0x0>;
			pinctrl-0 = <0x87 0x88>;
			pinctrl-1 = <0x89 0x8a 0x8b 0x8c>;
			pinctrl-2 = <0x8d>;
			pinctrl-3 = <0x8e 0x8f 0x90 0x91>;
			pinctrl-names = "default", "gf_spi_drive_6mA", "gf_cs_func", "gf_spi_drive_6mA_pulllow";
			status = "okay";
		};
	};

	fragment@43 {
		target = <0xffffffff>;

		__overlay__ {

			gpio_id0_default {
				phandle = <0xaa>;

				pins_cmd_dat {
					bias-pull-up = <0x0>;
					input-enable;
					pins = <0x1300>;
					slew-rate = <0x0>;
				};
			};
		};
	};

	fragment@44 {
		target = <0xffffffff>;

		__overlay__ {
			oppo,fp-id0 = <0xffffffff 0x13 0x0>;
			oppo,fp_gpio = <0x153>;

			goodix_id {
				chip-name = "G_OPTICAL_G3";
				eng-menu = "-1,-1";
				oppo,fp-id = <0x1>;
				vendor-chip = <0xb>;
			};

			goodix_id2 {
				chip-name = "E_OPTICAL_ET713";
				eng-menu = "-1,-1";
				oppo,fp-id = <0x0>;
				vendor-chip = <0xf>;
			};
		};
	};

	fragment@45 {
		target = <0xffffffff>;

		__overlay__ {

			adc_channel@ {
				compatible = "mediatek,adc_channel";
				mediatek,adc_fdd_rf_params_dynamic_custom_ch = <0x2>;
				mediatek,temperature0 = <0x0>;
				mediatek,temperature1 = <0x1>;
				status = "okay";
			};
		};
	};

	fragment@46 {
		target = <0xffffffff>;

		__overlay__ {
			mediatek,clkbuf-config = <0x2 0x1 0x1 0x2 0x0 0x0 0x1>;
			mediatek,clkbuf-driving-current = <0xffffffff 0xffffffff 0xffffffff 0xffffffff 0xffffffff 0xffffffff 0xffffffff>;
			mediatek,clkbuf-quantity = <0x7>;
			status = "okay";
		};
	};

	fragment@47 {
		target = <0xffffffff>;

		__overlay__ {
			#address-cells = <0x1>;
			#size-cells = <0x0>;
			clock-frequency = <0x61a80>;
			mediatek,use-open-drain;

			cap_touch@5d {
				compatible = "mediatek,cap_touch";
				phandle = <0xab>;
				reg = <0x5d>;
				status = "okay";
			};
		};
	};

	fragment@48 {
		target = <0xffffffff>;

		__overlay__ {
			#address-cells = <0x1>;
			#size-cells = <0x0>;
			clock-frequency = <0x61a80>;
			mediatek,use-open-drain;

			alsps@51 {
				compatible = "mediatek,alsps";
				interrupt-parent = <0xffffffff>;
				interrupts = <0x6 0x8 0x6 0x0>;
				phandle = <0xad>;
				reg = <0x51>;
				status = "okay";
			};

			barometer@77 {
				compatible = "mediatek,barometer";
				phandle = <0xae>;
				reg = <0x77>;
				status = "okay";
			};

			msensor@0c {
				compatible = "mediatek,msensor";
				phandle = <0xac>;
				reg = <0xc>;
				status = "okay";
			};
		};
	};

	fragment@49 {
		target = <0xffffffff>;

		__overlay__ {
			#address-cells = <0x1>;
			#size-cells = <0x0>;
			clock-frequency = <0x61a80>;
			mediatek,use-open-drain;

			camera_main_three@66 {
				compatible = "mediatek,camera_main_three";
				phandle = <0xb2>;
				reg = <0x66>;
				status = "okay";
			};

			camera_main_two@10 {
				compatible = "mediatek,camera_main_two";
				phandle = <0xaf>;
				reg = <0x10>;
				status = "okay";
			};

			camera_main_two_af@72 {
				compatible = "mediatek,camera_main_two_af";
				phandle = <0xb0>;
				reg = <0x72>;
				status = "okay";
			};

			camera_main_two_eeprom@51 {
				compatible = "mediatek,camera_main_two_eeprom";
				phandle = <0xb1>;
				reg = <0x51>;
				status = "okay";
			};

			ccu_sensor_i2c_2_hw@36 {
				compatible = "mediatek,ccu_sensor_i2c_2_hw";
				phandle = <0xb3>;
				reg = <0x36>;
				status = "okay";
			};
		};
	};

	fragment@5 {
		target = <0xffffffff>;

		__overlay__ {
			#address-cells = <0x1>;
			#size-cells = <0x0>;

			i2c_bl_lm3697@36 {
				compatible = "mediatek,i2c_bl_lm3697";
				reg = <0x36>;
				status = "okay";
			};

			i2c_lcd_bias@3e {
				compatible = "mediatek,i2c_lcd_bias";
				reg = <0x3e>;
				status = "okay";
			};
		};
	};

	fragment@50 {
		target = <0xffffffff>;

		__overlay__ {
			#address-cells = <0x1>;
			#size-cells = <0x0>;
			clock-frequency = <0x61a80>;
			mediatek,use-open-drain;

			nfc@08 {
				compatible = "mediatek,nfc";
				phandle = <0xb4>;
				reg = <0x8>;
				status = "okay";
			};
		};
	};

	fragment@51 {
		target = <0xffffffff>;

		__overlay__ {
			#address-cells = <0x1>;
			#size-cells = <0x0>;
			clock-frequency = <0x61a80>;
			mediatek,use-open-drain;

			camera_main@1a {
				compatible = "mediatek,camera_main";
				phandle = <0xb5>;
				reg = <0x1a>;
				status = "okay";
			};

			camera_main_af@72 {
				compatible = "mediatek,camera_main_af";
				phandle = <0xb6>;
				reg = <0x72>;
				status = "okay";
			};

			camera_main_eeprom@50 {
				compatible = "mediatek,camera_main_eeprom";
				phandle = <0xb7>;
				reg = <0x50>;
				status = "okay";
			};

			camera_sub@35 {
				compatible = "mediatek,camera_sub";
				phandle = <0xb8>;
				reg = <0x35>;
				status = "okay";
			};

			camera_sub_eeprom@54 {
				compatible = "mediatek,camera_sub_eeprom";
				phandle = <0xb9>;
				reg = <0x54>;
				status = "okay";
			};

			camera_sub_two@56 {
				compatible = "mediatek,camera_sub_two";
				phandle = <0xba>;
				reg = <0x56>;
				status = "okay";
			};

			ccu_sensor_i2c_4_hw@33 {
				compatible = "mediatek,ccu_sensor_i2c_4_hw";
				phandle = <0xbb>;
				reg = <0x33>;
				status = "okay";
			};

			strobe_main@63 {
				compatible = "mediatek,strobe_main";
				phandle = <0xbc>;
				reg = <0x63>;
				status = "okay";
			};

			strobe_main_2@64 {
				compatible = "mediatek,strobe_main_2";
				phandle = <0xbd>;
				reg = <0x64>;
				status = "okay";
			};
		};
	};

	fragment@52 {
		target = <0xffffffff>;

		__overlay__ {
			#address-cells = <0x1>;
			#size-cells = <0x0>;
			clock-frequency = <0x61a80>;
			mediatek,use-open-drain;

			subpmic_pmu@34 {
				compatible = "mediatek,subpmic_pmu";
				phandle = <0xbf>;
				reg = <0x34>;
				status = "okay";
			};

			usb_type_c@4e {
				compatible = "mediatek,usb_type_c";
				phandle = <0xbe>;
				reg = <0x4e>;
				status = "okay";
			};
		};
	};

	fragment@53 {
		target = <0xffffffff>;

		__overlay__ {
			#address-cells = <0x1>;
			#size-cells = <0x0>;
			clock-frequency = <0x61a80>;
			mediatek,use-open-drain;

			slave_charger@4b {
				compatible = "mediatek,slave_charger";
				phandle = <0xc0>;
				reg = <0x4b>;
				status = "okay";
			};
		};
	};

	fragment@54 {
		target = <0xffffffff>;

		__overlay__ {
			#address-cells = <0x1>;
			#size-cells = <0x0>;
			clock-frequency = <0x61a80>;
			mediatek,use-open-drain;
		};
	};

	fragment@55 {
		target = <0xffffffff>;

		__overlay__ {
			#address-cells = <0x1>;
			#size-cells = <0x0>;
			clock-frequency = <0x61a80>;
			mediatek,use-open-drain;
		};
	};

	fragment@56 {
		target = <0xffffffff>;

		__overlay__ {
			#address-cells = <0x1>;
			#size-cells = <0x0>;
			clock-frequency = <0x61a80>;
			mediatek,use-open-drain;
		};
	};

	fragment@57 {
		target = <0xffffffff>;

		__overlay__ {
			#address-cells = <0x1>;
			#size-cells = <0x0>;
			clock-frequency = <0x61a80>;
			mediatek,use-open-drain;
		};
	};

	fragment@58 {
		target = <0xffffffff>;

		__overlay__ {
			#address-cells = <0x1>;
			#size-cells = <0x0>;
			clock-frequency = <0x61a80>;
			mediatek,use-open-drain;
		};
	};

	fragment@59 {
		target = <0xffffffff>;

		__overlay__ {
			GPIO_FDD_BAND_SUPPORT_DETECT_2ND_PIN = <0xffffffff 0x6b 0x0>;
			GPIO_FDD_BAND_SUPPORT_DETECT_5TH_PIN = <0xffffffff 0x12 0x0>;
			GPIO_FDD_BAND_SUPPORT_DETECT_6TH_PIN = <0xffffffff 0x50 0x0>;
			GPIO_SIM1_HOT_PLUG = <0xffffffff 0x2f 0x0>;
			GPIO_SIM1_SCLK = <0xffffffff 0x26 0x0>;
			GPIO_SIM1_SIO = <0xffffffff 0x28 0x0>;
			GPIO_SIM1_SRST = <0xffffffff 0x27 0x0>;
			GPIO_SIM2_SCLK = <0xffffffff 0x25 0x0>;
			GPIO_SIM2_SIO = <0xffffffff 0x23 0x0>;
			GPIO_SIM2_SRST = <0xffffffff 0x24 0x0>;
		};
	};

	fragment@6 {
		target = <0xffffffff>;

		__overlay__ {

			default {
				phandle = <0x1c>;
			};

			lcd_mipi_err_en0_gpio {
				phandle = <0x23>;

				pins_cmd_dat {
					output-low;
					pinmux = <0x900>;
					slew-rate = <0x1>;
				};
			};

			lcd_mipi_err_en1_gpio {
				phandle = <0x24>;

				pins_cmd_dat {
					output-high;
					pinmux = <0x900>;
					slew-rate = <0x1>;
				};
			};

			lcd_vci_en0_gpio {
				phandle = <0x21>;

				pins_cmd_dat {
					output-low;
					pinmux = <0x2e00>;
					slew-rate = <0x1>;
				};
			};

			lcd_vci_en1_gpio {
				phandle = <0x22>;

				pins_cmd_dat {
					output-high;
					pinmux = <0x2e00>;
					slew-rate = <0x1>;
				};
			};

			lcm_rst_out0_gpio {
				phandle = <0x1f>;

				pins_cmd_dat {
					output-low;
					pinmux = <0x2d00>;
					slew-rate = <0x1>;
				};
			};

			lcm_rst_out1_gpio {
				phandle = <0x20>;

				pins_cmd_dat {
					output-high;
					pinmux = <0x2d00>;
					slew-rate = <0x1>;
				};
			};

			mode_te_gpio {
				phandle = <0x1d>;

				pins_cmd_dat {
					pinmux = <0x2c00>;
				};
			};

			mode_te_te {
				phandle = <0x1e>;

				pins_cmd_dat {
					pinmux = <0x2c01>;
				};
			};
		};
	};

	fragment@60 {
		target = <0xffffffff>;

		__overlay__ {
			gpio_init_default = <0x0 0x0 0x0 0x0 0x1 0x1 0x1 0x1 0x0 0x0 0x0 0x1 0x0 0x1 0x2 0x0 0x0 0x0 0x1 0x0 0x1 0x3 0x0 0x0 0x0 0x1 0x1 0x1 0x4 0x0 0x0 0x0 0x1 0x0 0x0 0x5 0x0 0x0 0x0 0x1 0x1 0x0 0x6 0x0 0x0 0x0 0x1 0x1 0x0 0x7 0x0 0x0 0x0 0x1 0x1 0x0 0x8 0x7 0x0 0x0 0x1 0x1 0x0 0x9 0x0 0x0 0x0 0x0 0x0 0x0 0xa 0x0 0x0 0x0 0x1 0x1 0x0 0xb 0x3 0x0 0x0 0x0 0x0 0x0 0xc 0x3 0x0 0x0 0x0 0x0 0x0 0xd 0x2 0x0 0x0 0x1 0x1 0x0 0xe 0x0 0x0 0x0 0x0 0x0 0x0 0xf 0x0 0x1 0x0 0x1 0x0 0x0 0x10 0x0 0x1 0x0 0x1 0x0 0x0 0x11 0x0 0x1 0x0 0x0 0x0 0x0 0x12 0x0 0x0 0x0 0x0 0x0 0x0 0x13 0x0 0x1 0x1 0x0 0x0 0x0 0x14 0x0 0x0 0x0 0x1 0x0 0x0 0x15 0x0 0x1 0x0 0x1 0x1 0x0 0x16 0x0 0x1 0x0 0x0 0x0 0x0 0x17 0x0 0x1 0x0 0x0 0x0 0x0 0x18 0x0 0x0 0x0 0x1 0x0 0x0 0x19 0x0 0x0 0x0 0x0 0x0 0x0 0x1a 0x0 0x0 0x0 0x0 0x0 0x0 0x1b 0x5 0x1 0x0 0x0 0x0 0x0 0x1c 0x5 0x0 0x0 0x1 0x1 0x0 0x1d 0x1 0x1 0x0 0x0 0x0 0x0 0x1e 0x1 0x0 0x0 0x1 0x1 0x0 0x1f 0x1 0x0 0x0 0x1 0x1 0x0 0x20 0x1 0x0 0x0 0x1 0x1 0x0 0x21 0x1 0x0 0x0 0x1 0x1 0x0 0x22 0x1 0x0 0x0 0x1 0x1 0x0 0x23 0x1 0x0 0x0 0x1 0x1 0x0 0x24 0x1 0x1 0x0 0x0 0x0 0x0 0x25 0x1 0x1 0x0 0x0 0x0 0x0 0x26 0x1 0x1 0x0 0x0 0x0 0x0 0x27 0x1 0x1 0x0 0x0 0x0 0x0 0x28 0x1 0x0 0x0 0x1 0x1 0x0 0x29 0x0 0x0 0x0 0x0 0x0 0x0 0x2a 0x0 0x1 0x0 0x0 0x0 0x0 0x2b 0x0 0x0 0x0 0x1 0x0 0x0 0x2c 0x1 0x0 0x0 0x1 0x0 0x0 0x2d 0x0 0x1 0x0 0x0 0x0 0x0 0x2e 0x0 0x1 0x0 0x0 0x0 0x0 0x2f 0x1 0x0 0x0 0x1 0x1 0x0 0x30 0x1 0x0 0x0 0x0 0x0 0x0 0x31 0x1 0x0 0x0 0x0 0x0 0x0 0x32 0x1 0x0 0x0 0x1 0x1 0x0 0x33 0x1 0x0 0x0 0x1 0x1 0x0 0x34 0x1 0x1 0x0 0x1 0x0 0x0 0x35 0x1 0x1 0x0 0x1 0x0 0x0 0x36 0x1 0x1 0x0 0x1 0x0 0x0 0x37 0x1 0x1 0x0 0x1 0x0 0x0 0x38 0x1 0x1 0x0 0x1 0x0 0x0 0x39 0x1 0x1 0x0 0x1 0x0 0x0 0x3a 0x0 0x0 0x0 0x1 0x0 0x0 0x3b 0x1 0x0 0x0 0x1 0x0 0x0 0x3c 0x1 0x0 0x0 0x1 0x0 0x0 0x3d 0x1 0x0 0x0 0x1 0x0 0x0 0x3e 0x1 0x0 0x0 0x1 0x0 0x0 0x3f 0x1 0x0 0x0 0x1 0x0 0x0 0x40 0x1 0x0 0x0 0x1 0x0 0x0 0x41 0x1 0x0 0x0 0x1 0x0 0x0 0x42 0x1 0x0 0x0 0x1 0x0 0x0 0x43 0x1 0x0 0x0 0x1 0x0 0x0 0x44 0x1 0x0 0x0 0x1 0x0 0x0 0x45 0x1 0x1 0x0 0x1 0x0 0x0 0x46 0x1 0x1 0x0 0x1 0x0 0x0 0x47 0x1 0x1 0x0 0x1 0x0 0x0 0x48 0x1 0x1 0x0 0x1 0x0 0x0 0x49 0x1 0x1 0x0 0x1 0x0 0x0 0x4a 0x1 0x1 0x0 0x1 0x0 0x0 0x4b 0x1 0x1 0x0 0x1 0x0 0x0 0x4c 0x1 0x1 0x0 0x1 0x0 0x0 0x4d 0x1 0x1 0x0 0x1 0x0 0x0 0x4e 0x1 0x1 0x0 0x1 0x0 0x0 0x4f 0x1 0x0 0x0 0x1 0x0 0x0 0x50 0x0 0x0 0x0 0x0 0x0 0x0 0x51 0x1 0x0 0x0 0x1 0x1 0x0 0x52 0x1 0x0 0x0 0x0 0x0 0x0 0x53 0x1 0x1 0x0 0x0 0x0 0x0 0x54 0x1 0x0 0x0 0x1 0x1 0x0 0x55 0x1 0x0 0x0 0x1 0x0 0x0 0x56 0x1 0x1 0x1 0x0 0x0 0x0 0x57 0x1 0x1 0x0 0x0 0x0 0x0 0x58 0x1 0x1 0x0 0x0 0x0 0x0 0x59 0x1 0x0 0x0 0x1 0x0 0x0 0x5a 0x1 0x1 0x0 0x0 0x0 0x0 0x5b 0x0 0x0 0x0 0x1 0x1 0x0 0x5c 0x1 0x1 0x0 0x1 0x0 0x0 0x5d 0x1 0x0 0x0 0x1 0x1 0x0 0x5e 0x1 0x0 0x0 0x1 0x1 0x0 0x5f 0x1 0x0 0x0 0x1 0x1 0x0 0x60 0x1 0x1 0x0 0x0 0x0 0x0 0x61 0x0 0x1 0x0 0x0 0x0 0x0 0x62 0x0 0x1 0x0 0x0 0x0 0x0 0x63 0x0 0x1 0x0 0x0 0x0 0x0 0x64 0x0 0x1 0x0 0x0 0x0 0x0 0x65 0x0 0x1 0x0 0x0 0x0 0x0 0x66 0x0 0x1 0x0 0x0 0x0 0x0 0x67 0x1 0x0 0x0 0x0 0x0 0x0 0x68 0x1 0x0 0x0 0x0 0x0 0x0 0x69 0x1 0x0 0x0 0x0 0x0 0x0 0x6a 0x1 0x0 0x0 0x0 0x0 0x0 0x6b 0x0 0x1 0x0 0x1 0x0 0x0 0x6c 0x0 0x1 0x0 0x0 0x0 0x0 0x6d 0x0 0x1 0x0 0x0 0x0 0x0 0x6e 0x0 0x1 0x0 0x0 0x0 0x0 0x6f 0x0 0x1 0x0 0x0 0x0 0x0 0x70 0x7 0x1 0x0 0x0 0x0 0x0 0x71 0x0 0x0 0x0 0x1 0x0 0x0 0x72 0x0 0x0 0x0 0x1 0x0 0x0 0x73 0x0 0x0 0x0 0x1 0x0 0x0 0x74 0x0 0x0 0x0 0x1 0x0 0x0 0x75 0x0 0x0 0x0 0x1 0x0 0x0 0x76 0x0 0x0 0x0 0x1 0x0 0x0 0x77 0x0 0x0 0x0 0x1 0x0 0x0 0x78 0x0 0x0 0x0 0x1 0x0 0x0 0x79 0x0 0x0 0x0 0x1 0x0 0x0 0x7a 0x1 0x0 0x0 0x1 0x1 0x0 0x7b 0x1 0x0 0x0 0x1 0x1 0x0 0x7c 0x1 0x1 0x0 0x0 0x0 0x0 0x7d 0x1 0x0 0x0 0x1 0x1 0x0 0x7e 0x1 0x0 0x0 0x1 0x1 0x0 0x7f 0x0 0x1 0x0 0x0 0x0 0x0 0x80 0x1 0x0 0x0 0x1 0x1 0x0 0x81 0x1 0x0 0x0 0x1 0x1 0x0 0x82 0x1 0x0 0x0 0x1 0x1 0x0 0x83 0x1 0x0 0x0 0x1 0x0 0x0 0x84 0x1 0x0 0x0 0x1 0x1 0x0 0x85 0x1 0x1 0x1 0x0 0x0 0x0 0x86 0x1 0x0 0x0 0x1 0x0 0x1 0x87 0x1 0x1 0x0 0x0 0x0 0x0 0x88 0x1 0x1 0x0 0x1 0x0 0x0 0x89 0x1 0x1 0x0 0x1 0x0 0x0 0x8a 0x1 0x1 0x0 0x0 0x0 0x0 0x8b 0x1 0x1 0x0 0x1 0x0 0x0 0x8c 0x1 0x0 0x0 0x0 0x0 0x0 0x8d 0x1 0x0 0x0 0x0 0x0 0x0 0x8e 0x1 0x0 0x0 0x0 0x0 0x0 0x8f 0x1 0x0 0x0 0x0 0x0 0x0 0x90 0x1 0x0 0x0 0x1 0x0 0x0 0x91 0x1 0x1 0x1 0x0 0x0 0x0 0x92 0x1 0x0 0x0 0x1 0x0 0x0 0x93 0x1 0x1 0x0 0x0 0x0 0x0 0x94 0x1 0x1 0x0 0x0 0x0 0x0 0x95 0x1 0x1 0x0 0x0 0x0 0x0 0x96 0x0 0x1 0x0 0x0 0x0 0x0 0x97 0x0 0x1 0x1 0x0 0x0 0x0 0x98 0x0 0x1 0x0 0x0 0x0 0x0 0x99 0x0 0x0 0x0 0x1 0x0 0x0 0x9a 0x1 0x1 0x0 0x0 0x0 0x0 0x9b 0x0 0x1 0x0 0x0 0x0 0x0 0x9c 0x0 0x1 0x0 0x0 0x0 0x0 0x9d 0x1 0x0 0x0 0x1 0x0 0x0 0x9e 0x0 0x0 0x0 0x1 0x1 0x0 0x9f 0x0 0x1 0x0 0x0 0x0 0x0 0xa0 0x0 0x1 0x0 0x0 0x0 0x0 0xa1 0x2 0x0 0x0 0x1 0x0 0x0 0xa2 0x2 0x1 0x1 0x0 0x0 0x0 0xa3 0x2 0x1 0x0 0x0 0x0 0x0 0xa4 0x2 0x1 0x0 0x0 0x0 0x0 0xa5 0x0 0x1 0x0 0x0 0x0 0x0 0xa6 0x0 0x1 0x0 0x0 0x0 0x0 0xa7 0x1 0x1 0x0 0x1 0x0 0x0 0xa8 0x1 0x1 0x0 0x1 0x0 0x0 0xa9 0x0 0x1 0x0 0x0 0x0 0x0 0xaa 0x2 0x1 0x0 0x1 0x0 0x0 0xab 0x2 0x1 0x0 0x1 0x0 0x0 0xac 0x2 0x1 0x0 0x1 0x0 0x0 0xad 0x0 0x0 0x0 0x1 0x0 0x0 0xae 0x2 0x0 0x0 0x1 0x0 0x0 0xaf 0x0 0x1 0x0 0x0 0x0 0x0 0xb0 0x0 0x1 0x0 0x0 0x0 0x0 0xb1 0x0 0x1 0x0 0x0 0x0 0x0 0xb2 0x0 0x1 0x0 0x0 0x0 0x0 0xb3 0x0 0x1 0x0 0x0 0x0 0x0 0xb4 0x0 0x0 0x0 0x1 0x0 0x0 0xb5 0x0 0x0 0x0 0x1 0x0 0x0 0xb6 0x0 0x0 0x0 0x1 0x0 0x0 0xb7 0x0 0x0 0x0 0x1 0x0 0x0 0xb8 0x0 0x0 0x0 0x1 0x0 0x0 0xb9 0x0 0x0 0x0 0x1 0x0 0x0 0xba 0x0 0x0 0x0 0x1 0x0 0x0 0xbb 0x0 0x0 0x0 0x1 0x0 0x0 0xbc 0x0 0x0 0x0 0x1 0x0 0x0 0xbd 0x0 0x0 0x0 0x1 0x0 0x0 0xbe 0x0 0x0 0x0 0x1 0x0 0x0 0xbf 0x0 0x0 0x0 0x1 0x0 0x0>;
		};
	};

	fragment@61 {
		target = <0xffffffff>;

		__overlay__ {
			deb-gpios = <0xffffffff 0x0 0x0>;
			debounce = <0x7d000>;
			interrupt-parent = <0xffffffff>;
			interrupts = <0x0 0x8 0x0 0x0>;
			status = "okay";
		};
	};

	fragment@62 {
		target = <0xffffffff>;

		__overlay__ {
			interrupt-parent = <0xffffffff>;
			interrupts = <0x1 0x2 0x1 0x0>;
			status = "okay";
		};
	};

	fragment@63 {
		target = <0xffffffff>;

		__overlay__ {
			interrupt-parent = <0xffffffff>;
			interrupts = <0x2 0x4 0x2 0x0>;
			status = "okay";
		};
	};

	fragment@64 {
		target = <0xffffffff>;

		__overlay__ {
			deb-gpios = <0xffffffff 0x3 0x0>;
			debounce = <0x3e8>;
			interrupt-parent = <0xffffffff>;
			interrupts = <0x3 0x8 0x3 0x0>;
			status = "okay";
		};
	};

	fragment@65 {
		target = <0xffffffff>;

		__overlay__ {
			interrupt-parent = <0xffffffff>;
			interrupts = <0x4 0x8 0x4 0x0>;
			status = "okay";
		};
	};

	fragment@66 {
		target = <0xffffffff>;

		__overlay__ {
			deb-gpios = <0xffffffff 0x7 0x0>;
			debounce = <0x3e800>;
			interrupt-parent = <0xffffffff>;
			interrupts = <0x7 0x8 0x7 0x0>;
			status = "okay";
		};
	};

	fragment@67 {
		target = <0xffffffff>;

		__overlay__ {
			interrupt-parent = <0xffffffff>;
			interrupts = <0x9 0x8 0x9 0x0>;
			status = "okay";
		};
	};

	fragment@68 {
		target = <0xffffffff>;

		__overlay__ {
			interrupt-parent = <0xffffffff>;
			interrupts = <0x14 0x1 0x14 0x0>;
			status = "okay";
		};
	};

	fragment@69 {
		target = <0xffffffff>;

		__overlay__ {
			interrupt-parent = <0xffffffff>;
			interrupts = <0x29 0x8 0x29 0x0>;
			status = "okay";
		};
	};

	fragment@7 {
		target = <0xffffffff>;

		__overlay__ {
			oppo_display_aod_ramless_support;
			oppo_display_aod_support;
			oppo_display_aodlight_support;
			oppo_display_dyn_data_rate = <0x45d>;
			oppo_display_dyn_dsi_hbp = <0x88>;
			oppo_display_elevenbits_support;
			oppo_display_ffl_support;
			oppo_display_fppress_support;
			oppo_display_hbm_support;
			oppo_display_panelid_support;
			oppo_display_panelnum_continue_support;
			oppo_display_sau_support;
			pinctrl-0 = <0x1c>;
			pinctrl-1 = <0x1d>;
			pinctrl-2 = <0x1e>;
			pinctrl-3 = <0x1f>;
			pinctrl-4 = <0x20>;
			pinctrl-5 = <0x21>;
			pinctrl-6 = <0x22>;
			pinctrl-7 = <0x23>;
			pinctrl-8 = <0x24>;
			pinctrl-names = "default", "mode_te_gpio", "mode_te_te", "lcm_rst_out0_gpio", "lcm_rst_out1_gpio", "lcd_vci_en0_gpio", "lcd_vci_en1_gpio", "lcd_mipi_err_en0_gpio", "lcd_mipi_err_en1_gpio";
			status = "okay";
		};
	};

	fragment@70 {
		target = <0xffffffff>;

		__overlay__ {
			interrupt-parent = <0xffffffff>;
			interrupts = <0x2c 0x1 0x2c 0x1>;
			status = "okay";
		};
	};

	fragment@71 {
		target = <0xffffffff>;

		__overlay__ {
			interrupt-parent = <0xffffffff>;
			interrupts = <0x5b 0x8 0x5b 0x0>;
			status = "okay";
		};
	};

	fragment@72 {
		target = <0xffffffff>;

		__overlay__ {
			interrupt-parent = <0xffffffff>;
			interrupts = <0xb6 0x4 0xbe 0x0>;
			status = "okay";
		};
	};

	fragment@73 {
		target = <0xffffffff>;

		__overlay__ {
			compatible = "mediatek,md1_sim1_hot_plug_eint-eint";
			debounce = <0x0 0x186a0>;
			dedicated = <0x0 0x0>;
			interrupts = <0x0 0x8>;
			sockettype = <0x0 0x0>;
			src_pin = <0x0 0x1>;
			status = "okay";
		};
	};

	fragment@74 {
		target = <0xffffffff>;

		__overlay__ {
			compatible = "mediatek,md1_sim2_hot_plug_eint-eint";
			debounce = <0x1 0x186a0>;
			dedicated = <0x1 0x0>;
			interrupts = <0x1 0x8>;
			sockettype = <0x1 0x0>;
			src_pin = <0x1 0x2>;
			status = "okay";
		};
	};

	fragment@75 {
		target = <0xffffffff>;

		__overlay__ {
			regulator-default-on = <0x1>;
			regulator-name = "vcama1";
			status = "okay";
		};
	};

	fragment@76 {
		target = <0xffffffff>;

		__overlay__ {
			regulator-default-on = <0x1>;
			regulator-name = "vcama2";
			status = "okay";
		};
	};

	fragment@77 {
		target = <0xffffffff>;

		__overlay__ {
			regulator-default-on = <0x1>;
			regulator-name = "vsim1";
			status = "okay";
		};
	};

	fragment@78 {
		target = <0xffffffff>;

		__overlay__ {
			regulator-default-on = <0x1>;
			regulator-name = "vsim2";
			status = "okay";
		};
	};

	fragment@79 {
		target = <0xffffffff>;

		__overlay__ {
			regulator-default-on = <0x1>;
			regulator-name = "vcamd";
			status = "okay";
		};
	};

	fragment@8 {
		target = <0xffffffff>;

		__overlay__ {
			status = "okay";

			goodix19151@5d {
				black_gesture_support;
				charger_pump_support;
				chip-name = "GT9886";
				compatible = "Goodix-gt9886";
				enable2v8_gpio = <0xffffffff 0x9f 0x1>;
				esd_handle_support;
				fingerprint_underscreen_support;
				fw_edge_limit_support;
				fw_update_app_support;
				game_switch_support;
				interrupt-parent = <0xffffffff>;
				interrupts = <0x1 0x2 0x1 0x0>;
				irq-gpio = <0xffffffff 0x1 0x2002>;
				pinctrl-names = "default";
				pressure_report_support;
				reg = <0x5d>;
				register-is-16bit;
				reset-gpio = <0xffffffff 0x96 0x0>;
				single_tap_support;
				smart_gesture_support;
				touchpanel,button-type = <0x4>;
				touchpanel,display-coords = <0x438 0x960>;
				touchpanel,max-num-support = <0xa>;
				touchpanel,panel-coords = <0x438 0x960>;
				touchpanel,touchmajor-limit = <0x0 0x36>;
				touchpanel,tx-rx-num = <0xf 0x22>;
				touchpanel.button-TRx = <0x0 0x0>;
			};
		};
	};

	fragment@80 {
		target = <0xffffffff>;

		__overlay__ {
			regulator-default-on = <0x1>;
			regulator-name = "vcamio";
			status = "okay";
		};
	};

	fragment@81 {
		target = <0xffffffff>;

		__overlay__ {
			regulator-default-on = <0x1>;
			regulator-name = "vldo28";
			status = "okay";
		};
	};

	fragment@82 {
		target = <0xffffffff>;

		__overlay__ {
			status = "okay";
			vcama-supply = <0xffffffff>;
			vcama_main2-supply = <0xffffffff>;
			vcama_main3-supply = <0xffffffff>;
			vcama_sub-supply = <0xffffffff>;
			vcama_sub2-supply = <0xffffffff>;
			vcamaf-supply = <0xffffffff>;
			vcamd_main2-supply = <0xffffffff>;
			vcamio-supply = <0xffffffff>;
			vcamio_main2-supply = <0xffffffff>;
			vcamio_main3-supply = <0xffffffff>;
			vcamio_sub-supply = <0xffffffff>;
			vcamio_sub2-supply = <0xffffffff>;
		};
	};

	fragment@83 {
		target = <0xffffffff>;

		__overlay__ {
			status = "okay";
			vtouch-supply = <0xffffffff>;
		};
	};

	fragment@84 {
		target = <0xffffffff>;

		__overlay__ {
			mediatek,kpd-hw-dl-key0 = <0x11>;
			mediatek,kpd-hw-dl-key1 = <0x0>;
			mediatek,kpd-hw-dl-key2 = <0x8>;
			mediatek,kpd-hw-factory-key = <0x0>;
			mediatek,kpd-hw-init-map = <0x72 0x0 0x0 0x0 0x0 0x0 0x0 0x0 0x0 0x0 0x0 0x0 0x0 0x0 0x0 0x0 0x0 0x0 0x0 0x0 0x0 0x0 0x0 0x0 0x0 0x0 0x0 0x0 0x0 0x0 0x0 0x0 0x0 0x0 0x0 0x0 0x0 0x0 0x0 0x0 0x0 0x0 0x0 0x0 0x0 0x0 0x0 0x0 0x0 0x0 0x0 0x0 0x0 0x0 0x0 0x0 0x0 0x0 0x0 0x0 0x0 0x0 0x0 0x0 0x0 0x0 0x0 0x0 0x0 0x0 0x0 0x0>;
			mediatek,kpd-hw-map-num = <0x48>;
			mediatek,kpd-hw-pwrkey = <0x8>;
			mediatek,kpd-hw-recovery-key = <0x11>;
			mediatek,kpd-hw-rstkey = <0x11>;
			mediatek,kpd-key-debounce = <0x400>;
			mediatek,kpd-pwkey-gpio-din = <0x0>;
			mediatek,kpd-pwrkey-eint-gpio = <0x0>;
			mediatek,kpd-sw-pwrkey = <0x74>;
			mediatek,kpd-sw-rstkey = <0x73>;
			mediatek,kpd-use-extend-type = <0x0>;
			status = "okay";
		};
	};

	fragment@85 {
		target = <0xffffffff>;

		__overlay__ {
			pinctrl-0 = <0x92>;
			pinctrl-1 = <0x93>;
			pinctrl-names = "i2c-state", "output-low-state";
		};
	};

	fragment@86 {
		target = <0xffffffff>;

		__overlay__ {

			i2c6_sda_i2c_state {
				phandle = <0x92>;

				pins_cmd_dat {
					bias-disable;
					pinmux = <0xc03>;
					slew-rate = <0x0>;
				};
			};

			i2c6_sda_output_low_state {
				phandle = <0x93>;

				pins_cmd_dat {
					output-low;
					pinmux = <0xc00>;
					slew-rate = <0x1>;
				};
			};
		};
	};

	fragment@87 {
		target = <0xffffffff>;

		__overlay__ {

			active@id1 {
				phandle = <0x11>;

				pins_cmd_dat {
					bias-pull-up;
					input-enable;
					pinmux = <0x3a00>;
					slew-rate = <0x0>;
				};
			};

			active@id2 {
				phandle = <0x12>;

				pins_cmd_dat {
					bias-pull-up;
					input-enable;
					pinmux = <0x9d00>;
					slew-rate = <0x0>;
				};
			};

			active@id5 {
				phandle = <0x13>;

				pins_cmd_dat {
					bias-pull-down;
					input-enable;
					pinmux = <0x1200>;
					slew-rate = <0x0>;
				};
			};

			active@id6 {
				phandle = <0x14>;

				pins_cmd_dat {
					bias-pull-down;
					input-enable;
					pinmux = <0x5000>;
					slew-rate = <0x0>;
				};
			};

			default@hw_sub_id {
				phandle = <0xe>;
			};

			sleep@id1 {
				phandle = <0xf>;

				pins_cmd_dat {
					bias-pull-down;
					input-enable;
					pinmux = <0x3a00>;
					slew-rate = <0x0>;
				};
			};

			sleep@id2 {
				phandle = <0x10>;

				pins_cmd_dat {
					bias-pull-down;
					input-enable;
					pinmux = <0x9d00>;
				};
			};
		};
	};

	fragment@9 {
		target = <0xffffffff>;

		__overlay__ {
			#address-cells = <0x1>;
			#size-cells = <0x0>;

			aw87339@59 {
				compatible = "awinic,aw87339_pa_spk";
				reg = <0x59>;
				reset-gpio = <0xffffffff 0x9c 0x0>;
				status = "okay";
			};
		};
	};
};
